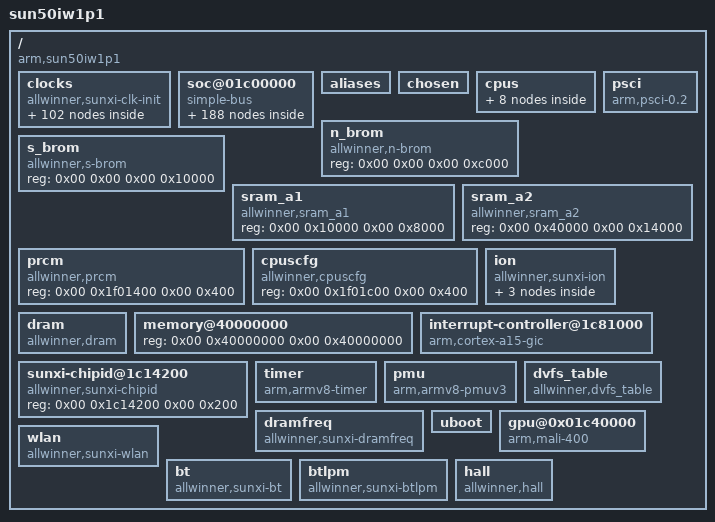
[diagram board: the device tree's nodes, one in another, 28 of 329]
/dts-v1/;

/memreserve/	0x0000000045000000 0x0000000000200000;
/memreserve/	0x0000000041010000 0x0000000000010000;
/memreserve/	0x0000000041020000 0x0000000000000800;
/memreserve/	0x0000000040100000 0x0000000000004000;
/memreserve/	0x0000000040104000 0x0000000000001000;
/memreserve/	0x0000000040105000 0x0000000000001000;
/ {
	model = "sun50iw1p1";
	compatible = "arm,sun50iw1p1\0arm,sun50iw1p1";
	interrupt-parent = < 0x01 >;
	#address-cells = < 0x02 >;
	#size-cells = < 0x02 >;

	clocks {
		compatible = "allwinner,sunxi-clk-init";
		device_type = "clocks";
		#address-cells = < 0x02 >;
		#size-cells = < 0x02 >;
		ranges;
		reg = < 0x00 0x1c20000 0x00 0x320 0x00 0x1f01400 0x00 0xb0 0x00 0x1f00060 0x00 0x04 >;

		losc {
			#clock-cells = < 0x00 >;
			compatible = "allwinner,fixed-clock";
			clock-frequency = < 0x8000 >;
			clock-output-names = "losc";
			linux,phandle = < 0x0c >;
			phandle = < 0x0c >;
		};

		iosc {
			#clock-cells = < 0x00 >;
			compatible = "allwinner,fixed-clock";
			clock-frequency = < 0xf42400 >;
			clock-output-names = "iosc";
			linux,phandle = < 0x0d >;
			phandle = < 0x0d >;
		};

		hosc {
			#clock-cells = < 0x00 >;
			compatible = "allwinner,fixed-clock";
			clock-frequency = < 0x16e3600 >;
			clock-output-names = "hosc";
			linux,phandle = < 0x06 >;
			phandle = < 0x06 >;
		};

		pll_cpu {
			#clock-cells = < 0x00 >;
			compatible = "allwinner,sunxi-pll-clock";
			lock-mode = "new";
			clock-output-names = "pll_cpu";
		};

		pll_audio {
			#clock-cells = < 0x00 >;
			compatible = "allwinner,sunxi-pll-clock";
			lock-mode = "new";
			assigned-clock-rates = < 0x1770000 >;
			clock-output-names = "pll_audio";
			linux,phandle = < 0x02 >;
			phandle = < 0x02 >;
		};

		pll_video0 {
			#clock-cells = < 0x00 >;
			compatible = "allwinner,sunxi-pll-clock";
			lock-mode = "new";
			assigned-clock-rates = < 0x11b3dc40 >;
			clock-output-names = "pll_video0";
			linux,phandle = < 0x03 >;
			phandle = < 0x03 >;
		};

		pll_ve {
			#clock-cells = < 0x00 >;
			compatible = "allwinner,sunxi-pll-clock";
			lock-mode = "new";
			clock-output-names = "pll_ve";
			linux,phandle = < 0x16 >;
			phandle = < 0x16 >;
		};

		pll_ddr0 {
			#clock-cells = < 0x00 >;
			compatible = "allwinner,sunxi-pll-clock";
			lock-mode = "new";
			clock-output-names = "pll_ddr0";
			linux,phandle = < 0x93 >;
			phandle = < 0x93 >;
		};

		pll_periph0 {
			#clock-cells = < 0x00 >;
			compatible = "allwinner,sunxi-pll-clock";
			lock-mode = "new";
			clock-output-names = "pll_periph0";
			linux,phandle = < 0x04 >;
			phandle = < 0x04 >;
		};

		pll_periph1 {
			#clock-cells = < 0x00 >;
			compatible = "allwinner,sunxi-pll-clock";
			lock-mode = "new";
			clock-output-names = "pll_periph1";
			linux,phandle = < 0x05 >;
			phandle = < 0x05 >;
		};

		pll_video1 {
			#clock-cells = < 0x00 >;
			compatible = "allwinner,sunxi-pll-clock";
			lock-mode = "new";
			assigned-clock-rates = < 0x11b3dc40 >;
			clock-output-names = "pll_video1";
		};

		pll_gpu {
			#clock-cells = < 0x00 >;
			compatible = "allwinner,sunxi-pll-clock";
			lock-mode = "new";
			clock-output-names = "pll_gpu";
			linux,phandle = < 0x96 >;
			phandle = < 0x96 >;
		};

		pll_mipi {
			#clock-cells = < 0x00 >;
			compatible = "allwinner,sunxi-pll-clock";
			lock-mode = "new";
			clock-output-names = "pll_mipi";
			linux,phandle = < 0x08 >;
			phandle = < 0x08 >;
		};

		pll_hsic {
			#clock-cells = < 0x00 >;
			compatible = "allwinner,sunxi-pll-clock";
			lock-mode = "new";
			clock-output-names = "pll_hsic";
			linux,phandle = < 0x3a >;
			phandle = < 0x3a >;
		};

		pll_de {
			#clock-cells = < 0x00 >;
			compatible = "allwinner,sunxi-pll-clock";
			lock-mode = "new";
			assigned-clock-rates = < 0x11b3dc40 >;
			clock-output-names = "pll_de";
			linux,phandle = < 0x07 >;
			phandle = < 0x07 >;
		};

		pll_ddr1 {
			#clock-cells = < 0x00 >;
			compatible = "allwinner,sunxi-pll-clock";
			lock-mode = "new";
			clock-output-names = "pll_ddr1";
			linux,phandle = < 0x94 >;
			phandle = < 0x94 >;
		};

		pll_audiox8 {
			#clock-cells = < 0x00 >;
			compatible = "allwinner,fixed-factor-clock";
			clocks = < 0x02 >;
			clock-mult = < 0x08 >;
			clock-div = < 0x01 >;
			clock-output-names = "pll_audiox8";
		};

		pll_audiox4 {
			#clock-cells = < 0x00 >;
			compatible = "allwinner,fixed-factor-clock";
			clocks = < 0x02 >;
			clock-mult = < 0x08 >;
			clock-div = < 0x02 >;
			clock-output-names = "pll_audiox4";
			linux,phandle = < 0x3c >;
			phandle = < 0x3c >;
		};

		pll_audiox2 {
			#clock-cells = < 0x00 >;
			compatible = "allwinner,fixed-factor-clock";
			clocks = < 0x02 >;
			clock-mult = < 0x08 >;
			clock-div = < 0x04 >;
			clock-output-names = "pll_audiox2";
		};

		pll_video0x2 {
			#clock-cells = < 0x00 >;
			compatible = "allwinner,fixed-factor-clock";
			clocks = < 0x03 >;
			clock-mult = < 0x02 >;
			clock-div = < 0x01 >;
			clock-output-names = "pll_video0x2";
		};

		pll_periph0x2 {
			#clock-cells = < 0x00 >;
			compatible = "allwinner,fixed-factor-clock";
			clocks = < 0x04 >;
			clock-mult = < 0x02 >;
			clock-div = < 0x01 >;
			clock-output-names = "pll_periph0x2";
			linux,phandle = < 0x7b >;
			phandle = < 0x7b >;
		};

		pll_periph1x2 {
			#clock-cells = < 0x00 >;
			compatible = "allwinner,fixed-factor-clock";
			clocks = < 0x05 >;
			clock-mult = < 0x02 >;
			clock-div = < 0x01 >;
			clock-output-names = "pll_periph1x2";
			linux,phandle = < 0x5a >;
			phandle = < 0x5a >;
		};

		pll_periph0d2 {
			#clock-cells = < 0x00 >;
			compatible = "allwinner,fixed-factor-clock";
			clocks = < 0x04 >;
			clock-mult = < 0x01 >;
			clock-div = < 0x02 >;
			clock-output-names = "pll_periph0d2";
		};

		hoscd2 {
			#clock-cells = < 0x00 >;
			compatible = "allwinner,fixed-factor-clock";
			clocks = < 0x06 >;
			clock-mult = < 0x01 >;
			clock-div = < 0x02 >;
			clock-output-names = "hoscd2";
		};

		cpu {
			#clock-cells = < 0x00 >;
			compatible = "allwinner,sunxi-periph-clock";
			clock-output-names = "cpu";
		};

		cpuapb {
			#clock-cells = < 0x00 >;
			compatible = "allwinner,sunxi-periph-clock";
			clock-output-names = "cpuapb";
		};

		axi {
			#clock-cells = < 0x00 >;
			compatible = "allwinner,sunxi-periph-clock";
			clock-output-names = "axi";
		};

		pll_periphahb0 {
			#clock-cells = < 0x00 >;
			compatible = "allwinner,sunxi-periph-clock";
			clock-output-names = "pll_periphahb0";
		};

		ahb1 {
			#clock-cells = < 0x00 >;
			compatible = "allwinner,sunxi-periph-clock";
			clock-output-names = "ahb1";
			linux,phandle = < 0x95 >;
			phandle = < 0x95 >;
		};

		apb1 {
			#clock-cells = < 0x00 >;
			compatible = "allwinner,sunxi-periph-clock";
			clock-output-names = "apb1";
		};

		apb2 {
			#clock-cells = < 0x00 >;
			compatible = "allwinner,sunxi-periph-clock";
			clock-output-names = "apb2";
			linux,phandle = < 0x7e >;
			phandle = < 0x7e >;
		};

		ahb2 {
			#clock-cells = < 0x00 >;
			compatible = "allwinner,sunxi-periph-clock";
			clock-output-names = "ahb2";
		};

		ths {
			#clock-cells = < 0x00 >;
			compatible = "allwinner,sunxi-periph-clock";
			clock-output-names = "ths";
			linux,phandle = < 0x84 >;
			phandle = < 0x84 >;
		};

		nand {
			#clock-cells = < 0x00 >;
			compatible = "allwinner,sunxi-periph-clock";
			clock-output-names = "nand";
			linux,phandle = < 0x80 >;
			phandle = < 0x80 >;
		};

		sdmmc0_mod {
			#clock-cells = < 0x00 >;
			compatible = "allwinner,sunxi-periph-clock";
			clock-output-names = "sdmmc0_mod";
			linux,phandle = < 0x60 >;
			phandle = < 0x60 >;
		};

		sdmmc0_bus {
			#clock-cells = < 0x00 >;
			compatible = "allwinner,sunxi-periph-clock";
			clock-output-names = "sdmmc0_bus";
			linux,phandle = < 0x61 >;
			phandle = < 0x61 >;
		};

		sdmmc0_rst {
			#clock-cells = < 0x00 >;
			compatible = "allwinner,sunxi-periph-clock";
			clock-output-names = "sdmmc0_rst";
			linux,phandle = < 0x62 >;
			phandle = < 0x62 >;
		};

		sdmmc1_mod {
			#clock-cells = < 0x00 >;
			compatible = "allwinner,sunxi-periph-clock";
			clock-output-names = "sdmmc1_mod";
			linux,phandle = < 0x65 >;
			phandle = < 0x65 >;
		};

		sdmmc1_bus {
			#clock-cells = < 0x00 >;
			compatible = "allwinner,sunxi-periph-clock";
			clock-output-names = "sdmmc1_bus";
			linux,phandle = < 0x66 >;
			phandle = < 0x66 >;
		};

		sdmmc1_rst {
			#clock-cells = < 0x00 >;
			compatible = "allwinner,sunxi-periph-clock";
			clock-output-names = "sdmmc1_rst";
			linux,phandle = < 0x67 >;
			phandle = < 0x67 >;
		};

		sdmmc2_mod {
			#clock-cells = < 0x00 >;
			compatible = "allwinner,sunxi-periph-clock";
			clock-output-names = "sdmmc2_mod";
			linux,phandle = < 0x5b >;
			phandle = < 0x5b >;
		};

		sdmmc2_bus {
			#clock-cells = < 0x00 >;
			compatible = "allwinner,sunxi-periph-clock";
			clock-output-names = "sdmmc2_bus";
			linux,phandle = < 0x5c >;
			phandle = < 0x5c >;
		};

		sdmmc2_rst {
			#clock-cells = < 0x00 >;
			compatible = "allwinner,sunxi-periph-clock";
			clock-output-names = "sdmmc2_rst";
			linux,phandle = < 0x5d >;
			phandle = < 0x5d >;
		};

		ts {
			#clock-cells = < 0x00 >;
			compatible = "allwinner,sunxi-periph-clock";
			clock-output-names = "ts";
		};

		ce {
			#clock-cells = < 0x00 >;
			compatible = "allwinner,sunxi-periph-clock";
			clock-output-names = "ce";
			linux,phandle = < 0x7a >;
			phandle = < 0x7a >;
		};

		spi0 {
			#clock-cells = < 0x00 >;
			compatible = "allwinner,sunxi-periph-clock";
			clock-output-names = "spi0";
			linux,phandle = < 0x52 >;
			phandle = < 0x52 >;
		};

		spi1 {
			#clock-cells = < 0x00 >;
			compatible = "allwinner,sunxi-periph-clock";
			clock-output-names = "spi1";
			linux,phandle = < 0x56 >;
			phandle = < 0x56 >;
		};

		i2s0 {
			#clock-cells = < 0x00 >;
			compatible = "allwinner,sunxi-periph-clock";
			clock-output-names = "i2s0";
			linux,phandle = < 0x42 >;
			phandle = < 0x42 >;
		};

		i2s1 {
			#clock-cells = < 0x00 >;
			compatible = "allwinner,sunxi-periph-clock";
			clock-output-names = "i2s1";
			linux,phandle = < 0x47 >;
			phandle = < 0x47 >;
		};

		i2s2 {
			#clock-cells = < 0x00 >;
			compatible = "allwinner,sunxi-periph-clock";
			clock-output-names = "i2s2";
			linux,phandle = < 0x48 >;
			phandle = < 0x48 >;
		};

		spdif {
			#clock-cells = < 0x00 >;
			compatible = "allwinner,sunxi-periph-clock";
			clock-output-names = "spdif";
			linux,phandle = < 0x49 >;
			phandle = < 0x49 >;
		};

		usbphy0 {
			#clock-cells = < 0x00 >;
			compatible = "allwinner,sunxi-periph-clock";
			clock-output-names = "usbphy0";
			linux,phandle = < 0x32 >;
			phandle = < 0x32 >;
		};

		usbphy1 {
			#clock-cells = < 0x00 >;
			compatible = "allwinner,sunxi-periph-clock";
			clock-output-names = "usbphy1";
			linux,phandle = < 0x36 >;
			phandle = < 0x36 >;
		};

		usbhsic {
			#clock-cells = < 0x00 >;
			compatible = "allwinner,sunxi-periph-clock";
			clock-output-names = "usbhsic";
			linux,phandle = < 0x38 >;
			phandle = < 0x38 >;
		};

		usbhsic12m {
			#clock-cells = < 0x00 >;
			compatible = "allwinner,sunxi-periph-clock";
			clock-output-names = "usbhsic12m";
			linux,phandle = < 0x39 >;
			phandle = < 0x39 >;
		};

		usbohci1 {
			#clock-cells = < 0x00 >;
			compatible = "allwinner,sunxi-periph-clock";
			clock-output-names = "usbohci1";
			linux,phandle = < 0x3b >;
			phandle = < 0x3b >;
		};

		usbohci0 {
			#clock-cells = < 0x00 >;
			compatible = "allwinner,sunxi-periph-clock";
			clock-output-names = "usbohci0";
			linux,phandle = < 0x35 >;
			phandle = < 0x35 >;
		};

		de {
			#clock-cells = < 0x00 >;
			compatible = "allwinner,sunxi-periph-clock";
			assigned-clock-parents = < 0x07 >;
			assigned-clock-rates = < 0x11b3dc40 >;
			clock-output-names = "de";
			linux,phandle = < 0x6a >;
			phandle = < 0x6a >;
		};

		tcon0 {
			#clock-cells = < 0x00 >;
			compatible = "allwinner,sunxi-periph-clock";
			assigned-clock-parents = < 0x08 >;
			clock-output-names = "tcon0";
			linux,phandle = < 0x6b >;
			phandle = < 0x6b >;
		};

		tcon1 {
			#clock-cells = < 0x00 >;
			compatible = "allwinner,sunxi-periph-clock";
			assigned-clock-parents = < 0x03 >;
			clock-output-names = "tcon1";
			linux,phandle = < 0x6c >;
			phandle = < 0x6c >;
		};

		deinterlace {
			#clock-cells = < 0x00 >;
			compatible = "allwinner,sunxi-periph-clock";
			clock-output-names = "deinterlace";
			linux,phandle = < 0x7c >;
			phandle = < 0x7c >;
		};

		csi_s {
			#clock-cells = < 0x00 >;
			compatible = "allwinner,sunxi-periph-clock";
			clock-output-names = "csi_s";
			linux,phandle = < 0x73 >;
			phandle = < 0x73 >;
		};

		csi_m {
			#clock-cells = < 0x00 >;
			compatible = "allwinner,sunxi-periph-clock";
			clock-output-names = "csi_m";
			linux,phandle = < 0x74 >;
			phandle = < 0x74 >;
		};

		csi_misc {
			#clock-cells = < 0x00 >;
			compatible = "allwinner,sunxi-periph-clock";
			clock-output-names = "csi_misc";
			linux,phandle = < 0x75 >;
			phandle = < 0x75 >;
		};

		ve {
			#clock-cells = < 0x00 >;
			compatible = "allwinner,sunxi-periph-clock";
			clock-output-names = "ve";
			linux,phandle = < 0x17 >;
			phandle = < 0x17 >;
		};

		adda {
			#clock-cells = < 0x00 >;
			compatible = "allwinner,sunxi-periph-clock";
			clock-output-names = "adda";
			linux,phandle = < 0x41 >;
			phandle = < 0x41 >;
		};

		addax4 {
			#clock-cells = < 0x00 >;
			compatible = "allwinner,sunxi-periph-clock";
			clock-output-names = "addax4";
		};

		avs {
			#clock-cells = < 0x00 >;
			compatible = "allwinner,sunxi-periph-clock";
			clock-output-names = "avs";
		};

		hdmi {
			#clock-cells = < 0x00 >;
			compatible = "allwinner,sunxi-periph-clock";
			assigned-clock-parents = < 0x03 >;
			clock-output-names = "hdmi";
			linux,phandle = < 0x6f >;
			phandle = < 0x6f >;
		};

		hdmi_slow {
			#clock-cells = < 0x00 >;
			compatible = "allwinner,sunxi-periph-clock";
			clock-output-names = "hdmi_slow";
			linux,phandle = < 0x70 >;
			phandle = < 0x70 >;
		};

		mbus {
			#clock-cells = < 0x00 >;
			compatible = "allwinner,sunxi-periph-clock";
			clock-output-names = "mbus";
		};

		mipidsi {
			#clock-cells = < 0x00 >;
			compatible = "allwinner,sunxi-periph-clock";
			clock-output-names = "mipidsi";
			linux,phandle = < 0x6e >;
			phandle = < 0x6e >;
		};

		gpu {
			#clock-cells = < 0x00 >;
			compatible = "allwinner,sunxi-periph-clock";
			clock-output-names = "gpu";
			linux,phandle = < 0x97 >;
			phandle = < 0x97 >;
		};

		usbehci_16 {
			#clock-cells = < 0x00 >;
			compatible = "allwinner,sunxi-periph-clock";
			clock-output-names = "usbohci_16";
		};

		usbehci1 {
			#clock-cells = < 0x00 >;
			compatible = "allwinner,sunxi-periph-clock";
			clock-output-names = "usbehci1";
			linux,phandle = < 0x37 >;
			phandle = < 0x37 >;
		};

		usbehci0 {
			#clock-cells = < 0x00 >;
			compatible = "allwinner,sunxi-periph-clock";
			clock-output-names = "usbehci0";
			linux,phandle = < 0x34 >;
			phandle = < 0x34 >;
		};

		usbotg {
			#clock-cells = < 0x00 >;
			compatible = "allwinner,sunxi-periph-clock";
			clock-output-names = "usbotg";
			linux,phandle = < 0x33 >;
			phandle = < 0x33 >;
		};

		gmac {
			#clock-cells = < 0x00 >;
			compatible = "allwinner,sunxi-periph-clock";
			clock-output-names = "gmac";
			linux,phandle = < 0x8f >;
			phandle = < 0x8f >;
		};

		sdram {
			#clock-cells = < 0x00 >;
			compatible = "allwinner,sunxi-periph-clock";
			clock-output-names = "sdram";
		};

		dma {
			#clock-cells = < 0x00 >;
			compatible = "allwinner,sunxi-periph-clock";
			clock-output-names = "dma";
			linux,phandle = < 0x0b >;
			phandle = < 0x0b >;
		};

		hwspinlock_rst {
			#clock-cells = < 0x00 >;
			compatible = "allwinner,sunxi-periph-clock";
			clock-output-names = "hwspinlock_rst";
			linux,phandle = < 0x0f >;
			phandle = < 0x0f >;
		};

		hwspinlock_bus {
			#clock-cells = < 0x00 >;
			compatible = "allwinner,sunxi-periph-clock";
			clock-output-names = "hwspinlock_bus";
			linux,phandle = < 0x10 >;
			phandle = < 0x10 >;
		};

		msgbox {
			#clock-cells = < 0x00 >;
			compatible = "allwinner,sunxi-periph-clock";
			clock-output-names = "msgbox";
			linux,phandle = < 0x0e >;
			phandle = < 0x0e >;
		};

		lvds {
			#clock-cells = < 0x00 >;
			compatible = "allwinner,sunxi-periph-clock";
			clock-output-names = "lvds";
			linux,phandle = < 0x6d >;
			phandle = < 0x6d >;
		};

		uart0 {
			#clock-cells = < 0x00 >;
			compatible = "allwinner,sunxi-periph-clock";
			clock-output-names = "uart0";
			linux,phandle = < 0x18 >;
			phandle = < 0x18 >;
		};

		uart1 {
			#clock-cells = < 0x00 >;
			compatible = "allwinner,sunxi-periph-clock";
			clock-output-names = "uart1";
			linux,phandle = < 0x1b >;
			phandle = < 0x1b >;
		};

		uart2 {
			#clock-cells = < 0x00 >;
			compatible = "allwinner,sunxi-periph-clock";
			clock-output-names = "uart2";
			linux,phandle = < 0x1e >;
			phandle = < 0x1e >;
		};

		uart3 {
			#clock-cells = < 0x00 >;
			compatible = "allwinner,sunxi-periph-clock";
			clock-output-names = "uart3";
			linux,phandle = < 0x21 >;
			phandle = < 0x21 >;
		};

		uart4 {
			#clock-cells = < 0x00 >;
			compatible = "allwinner,sunxi-periph-clock";
			clock-output-names = "uart4";
			linux,phandle = < 0x24 >;
			phandle = < 0x24 >;
		};

		scr {
			#clock-cells = < 0x00 >;
			compatible = "allwinner,sunxi-periph-clock";
			clock-output-names = "scr";
			linux,phandle = < 0x7d >;
			phandle = < 0x7d >;
		};

		twi0 {
			#clock-cells = < 0x00 >;
			compatible = "allwinner,sunxi-periph-clock";
			clock-output-names = "twi0";
			linux,phandle = < 0x27 >;
			phandle = < 0x27 >;
		};

		twi1 {
			#clock-cells = < 0x00 >;
			compatible = "allwinner,sunxi-periph-clock";
			clock-output-names = "twi1";
			linux,phandle = < 0x2a >;
			phandle = < 0x2a >;
		};

		twi2 {
			#clock-cells = < 0x00 >;
			compatible = "allwinner,sunxi-periph-clock";
			clock-output-names = "twi2";
			linux,phandle = < 0x2d >;
			phandle = < 0x2d >;
		};

		twi3 {
			#clock-cells = < 0x00 >;
			compatible = "allwinner,sunxi-periph-clock";
			clock-output-names = "twi3";
		};

		pio {
			#clock-cells = < 0x00 >;
			compatible = "allwinner,sunxi-periph-clock";
			clock-output-names = "pio";
			linux,phandle = < 0x0a >;
			phandle = < 0x0a >;
		};

		cpurcir {
			#clock-cells = < 0x00 >;
			compatible = "allwinner,sunxi-periph-cpus-clock";
			clock-output-names = "cpurcir";
			linux,phandle = < 0x12 >;
			phandle = < 0x12 >;
		};

		cpurpio {
			#clock-cells = < 0x00 >;
			compatible = "allwinner,sunxi-periph-cpus-clock";
			clock-output-names = "cpurpio";
			linux,phandle = < 0x09 >;
			phandle = < 0x09 >;
		};

		cpurpll_peri0 {
			#clock-cells = < 0x00 >;
			compatible = "allwinner,sunxi-periph-cpus-clock";
			clock-output-names = "cpurpll_peri0";
		};

		cpurcpus {
			#clock-cells = < 0x00 >;
			compatible = "allwinner,sunxi-periph-cpus-clock";
			clock-output-names = "cpurcpus";
		};

		cpurahbs {
			#clock-cells = < 0x00 >;
			compatible = "allwinner,sunxi-periph-cpus-clock";
			clock-output-names = "cpurahbs";
		};

		cpurapbs {
			#clock-cells = < 0x00 >;
			compatible = "allwinner,sunxi-periph-cpus-clock";
			clock-output-names = "cpurapbs";
		};

		losc_out {
			#clock-cells = < 0x00 >;
			compatible = "allwinner,sunxi-periph-cpus-clock";
			clock-output-names = "losc_out";
			linux,phandle = < 0x98 >;
			phandle = < 0x98 >;
		};
	};

	soc@01c00000 {
		compatible = "simple-bus";
		#address-cells = < 0x02 >;
		#size-cells = < 0x02 >;
		ranges;
		device_type = "soc";

		pinctrl@01f02c00 {
			compatible = "allwinner,sun50i-r-pinctrl";
			reg = < 0x00 0x1f02c00 0x00 0x400 >;
			interrupts = < 0x00 0x2d 0x04 >;
			clocks = < 0x09 >;
			device_type = "r_pio";
			gpio-controller;
			interrupt-controller;
			#interrupt-cells = < 0x02 >;
			#size-cells = < 0x00 >;
			#gpio-cells = < 0x06 >;
			linux,phandle = < 0x79 >;
			phandle = < 0x79 >;

			s_cir0@0 {
				allwinner,pins = "PL11";
				allwinner,function = "s_cir0";
				allwinner,muxsel = < 0x02 >;
				allwinner,drive = < 0x02 >;
				allwinner,pull = < 0x01 >;
				linux,phandle = < 0x11 >;
				phandle = < 0x11 >;
			};

			pwm16@0 {
				linux,phandle = < 0xbd >;
				phandle = < 0xbd >;
				allwinner,pins = "PL10";
				allwinner,function = "pwm16";
				allwinner,pname = "pwm_positive";
				allwinner,muxsel = < 0x02 >;
				allwinner,pull = < 0x00 >;
				allwinner,drive = < 0xffffffff >;
				allwinner,data = < 0xffffffff >;
			};

			pwm16@1 {
				linux,phandle = < 0xbe >;
				phandle = < 0xbe >;
				allwinner,pins = "PL10";
				allwinner,function = "pwm16";
				allwinner,pname = "pwm_positive";
				allwinner,muxsel = < 0x07 >;
				allwinner,pull = < 0x00 >;
				allwinner,drive = < 0xffffffff >;
				allwinner,data = < 0xffffffff >;
			};

			s_uart0@0 {
				linux,phandle = < 0xc4 >;
				phandle = < 0xc4 >;
				allwinner,pins = "PL2\0PL3";
				allwinner,function = "s_uart0";
				allwinner,pname = "s_uart0_tx\0s_uart0_rx";
				allwinner,muxsel = < 0x02 >;
				allwinner,pull = < 0xffffffff >;
				allwinner,drive = < 0xffffffff >;
				allwinner,data = < 0xffffffff >;
			};

			s_rsb0@0 {
				linux,phandle = < 0xc5 >;
				phandle = < 0xc5 >;
				allwinner,pins = "PL0\0PL1";
				allwinner,function = "s_rsb0";
				allwinner,pname = "s_rsb0_sck\0s_rsb0_sda";
				allwinner,muxsel = < 0x02 >;
				allwinner,pull = < 0x01 >;
				allwinner,drive = < 0x02 >;
				allwinner,data = < 0xffffffff >;
			};

			s_jtag0@0 {
				linux,phandle = < 0xc6 >;
				phandle = < 0xc6 >;
				allwinner,pins = "PL4\0PL5\0PL6\0PL7";
				allwinner,function = "s_jtag0";
				allwinner,pname = "s_jtag0_tms\0s_jtag0_tck\0s_jtag0_tdo\0s_jtag0_tdi";
				allwinner,muxsel = < 0x02 >;
				allwinner,pull = < 0x01 >;
				allwinner,drive = < 0x02 >;
				allwinner,data = < 0xffffffff >;
			};
		};

		pinctrl@01c20800 {
			compatible = "allwinner,sun50i-pinctrl";
			reg = < 0x00 0x1c20800 0x00 0x400 >;
			interrupts = < 0x00 0x0b 0x04 0x00 0x11 0x04 0x00 0x15 0x04 >;
			device_type = "pio";
			clocks = < 0x0a >;
			gpio-controller;
			interrupt-controller;
			#interrupt-cells = < 0x02 >;
			#size-cells = < 0x00 >;
			#gpio-cells = < 0x06 >;
			linux,phandle = < 0x30 >;
			phandle = < 0x30 >;

			sdc0@1 {
				allwinner,pins = "PF0\0PF1\0PF2\0PF3\0PF4\0PF5";
				allwinner,function = "io_disabled";
				allwinner,muxsel = < 0x07 >;
				allwinner,drive = < 0x01 >;
				allwinner,pull = < 0x01 >;
				linux,phandle = < 0x64 >;
				phandle = < 0x64 >;
			};

			sdc1@1 {
				allwinner,pins = "PG0\0PG1\0PG2\0PG3\0PG4\0PG5";
				allwinner,function = "io_disabled";
				allwinner,muxsel = < 0x07 >;
				allwinner,drive = < 0x01 >;
				allwinner,pull = < 0x01 >;
				linux,phandle = < 0x69 >;
				phandle = < 0x69 >;
			};

			sdc2@1 {
				allwinner,pins = "PC1\0PC5\0PC6\0PC8\0PC9\0PC10\0PC11\0PC12\0PC13\0PC14\0PC15\0PC16";
				allwinner,function = "io_disabled";
				allwinner,muxsel = < 0x07 >;
				allwinner,drive = < 0x01 >;
				allwinner,pull = < 0x01 >;
				linux,phandle = < 0x5f >;
				phandle = < 0x5f >;
			};

			daudio0@0 {
				allwinner,pins = "PB6\0PB3\0PB4\0PB5\0PB7";
				allwinner,function = "pcm0";
				allwinner,muxsel = < 0x03 >;
				allwinner,drive = < 0x01 >;
				allwinner,pull = < 0x00 >;
				linux,phandle = < 0x43 >;
				phandle = < 0x43 >;
			};

			daudio0_sleep@0 {
				allwinner,pins = "PB6\0PB3\0PB4\0PB5\0PB7";
				allwinner,function = "io_disabled";
				allwinner,muxsel = < 0x07 >;
				allwinner,drive = < 0x01 >;
				allwinner,pull = < 0x00 >;
				linux,phandle = < 0x44 >;
				phandle = < 0x44 >;
			};

			daudio1@0 {
				allwinner,pins = "PG10\0PG11\0PG12\0PG13";
				allwinner,function = "pcm1";
				allwinner,muxsel = < 0x03 >;
				allwinner,drive = < 0x01 >;
				allwinner,pull = < 0x00 >;
				linux,phandle = < 0x45 >;
				phandle = < 0x45 >;
			};

			daudio1_sleep@0 {
				allwinner,pins = "PG10\0PG11\0PG12\0PG13";
				allwinner,function = "io_disabled";
				allwinner,muxsel = < 0x07 >;
				allwinner,drive = < 0x01 >;
				allwinner,pull = < 0x00 >;
				linux,phandle = < 0x46 >;
				phandle = < 0x46 >;
			};

			aif3@0 {
				allwinner,pins = "PG10\0PG11\0PG12\0PG13";
				allwinner,function = "aif3";
				allwinner,muxsel = < 0x02 >;
				allwinner,drive = < 0x01 >;
				allwinner,pull = < 0x00 >;
				linux,phandle = < 0x3e >;
				phandle = < 0x3e >;
			};

			aif2_sleep@0 {
				allwinner,pins = "PB6\0PB4\0PB5\0PB7";
				allwinner,function = "io_disabled";
				allwinner,muxsel = < 0x07 >;
				allwinner,drive = < 0x01 >;
				allwinner,pull = < 0x00 >;
				linux,phandle = < 0x3f >;
				phandle = < 0x3f >;
			};

			aif3_sleep@0 {
				allwinner,pins = "PG10\0PG11\0PG12\0PG13";
				allwinner,function = "io_disabled";
				allwinner,muxsel = < 0x07 >;
				allwinner,drive = < 0x01 >;
				allwinner,pull = < 0x00 >;
				linux,phandle = < 0x40 >;
				phandle = < 0x40 >;
			};

			spdif@0 {
				allwinner,pins = "PH8";
				allwinner,function = "spdif0";
				allwinner,muxsel = < 0x02 >;
				allwinner,drive = < 0x01 >;
				allwinner,pull = < 0x00 >;
				linux,phandle = < 0x4a >;
				phandle = < 0x4a >;
			};

			spdif_sleep@0 {
				allwinner,pins = "PH8";
				allwinner,function = "io_disabled";
				allwinner,muxsel = < 0x07 >;
				allwinner,drive = < 0x01 >;
				allwinner,pull = < 0x00 >;
				linux,phandle = < 0x4b >;
				phandle = < 0x4b >;
			};

			csi0_sleep@0 {
				allwinner,pins = "PE0\0PE2\0PE3\0PE4\0PE5\0PE6\0PE7\0PE8\0PE9\0PE10\0PE11\0PE12\0PE13";
				allwinner,pname = "csi0_pck\0csi0_hsync\0csi0_vsync\0csi0_d0\0csi0_d1\0csi0_d2\0csi0_d3\0csi0_d4\0csi0_d5\0csi0_d6\0csi0_d7\0csi0_sck\0csi0_sda";
				allwinner,function = "io_disabled";
				allwinner,muxsel = < 0x07 >;
				allwinner,drive = < 0x01 >;
				allwinner,pull = < 0x00 >;
				allwinner,data = < 0x00 >;
				linux,phandle = < 0x77 >;
				phandle = < 0x77 >;
			};

			smartcard@0 {
				allwinner,pins = "PB1\0PB4\0PB5\0PB6\0PB7";
				allwinner,function = "sim0";
				allwinner,muxsel = < 0x05 >;
				allwinner,drive = < 0x01 >;
				allwinner,pull = < 0x01 >;
				linux,phandle = < 0x7f >;
				phandle = < 0x7f >;
			};

			nand0@2 {
				allwinner,pins = "PC0\0PC1\0PC2\0PC3\0PC4\0PC5\0PC6\0PC7\0PC8\0PC9\0PC10\0PC11\0PC12\0PC13\0PC14\0PC15\0PC16\0PC17\0PC18";
				allwinner,function = "io_disabled";
				allwinner,muxsel = < 0x07 >;
				allwinner,drive = < 0x01 >;
				allwinner,pull = < 0x00 >;
				linux,phandle = < 0x83 >;
				phandle = < 0x83 >;
			};

			gmac@0 {
				allwinner,pins = "PD8\0PD9\0PD10\0PD11\0PD12\0PD13\0PD14\0PD15\0PD16\0PD17\0PD18\0PD19\0PD20\0PD21\0PD22\0PD23";
				allwinner,function = "gmac0";
				allwinner,muxsel = < 0x04 >;
				allwinner,drive = < 0x03 >;
				allwinner,pull = < 0x00 >;
				linux,phandle = < 0x8e >;
				phandle = < 0x8e >;
			};

			card0_boot_para@0 {
				linux,phandle = < 0x99 >;
				phandle = < 0x99 >;
				allwinner,pins = "PF0\0PF1\0PF2\0PF3\0PF4\0PF5";
				allwinner,function = "card0_boot_para";
				allwinner,pname = "sdc_d1\0sdc_d0\0sdc_clk\0sdc_cmd\0sdc_d3\0sdc_d2";
				allwinner,muxsel = < 0x02 >;
				allwinner,pull = < 0x01 >;
				allwinner,drive = < 0x02 >;
				allwinner,data = < 0xffffffff >;
			};

			card2_boot_para@0 {
				linux,phandle = < 0x9a >;
				phandle = < 0x9a >;
				allwinner,pins = "PC1\0PC5\0PC6\0PC8\0PC9\0PC10\0PC11\0PC12\0PC13\0PC14\0PC15\0PC16";
				allwinner,function = "card2_boot_para";
				allwinner,pname = "sdc_ds\0sdc_clk\0sdc_cmd\0sdc_d0\0sdc_d1\0sdc_d2\0sdc_d3\0sdc_d4\0sdc_d5\0sdc_d6\0sdc_d7\0sdc_emmc_rst";
				allwinner,muxsel = < 0x03 >;
				allwinner,pull = < 0x01 >;
				allwinner,drive = < 0x03 >;
				allwinner,data = < 0xffffffff >;
			};

			twi_para@0 {
				linux,phandle = < 0x9b >;
				phandle = < 0x9b >;
				allwinner,pins = "PH0\0PH1";
				allwinner,function = "twi_para";
				allwinner,pname = "twi_scl\0twi_sda";
				allwinner,muxsel = < 0x02 >;
				allwinner,pull = < 0xffffffff >;
				allwinner,drive = < 0xffffffff >;
				allwinner,data = < 0xffffffff >;
			};

			uart_para@0 {
				linux,phandle = < 0x9c >;
				phandle = < 0x9c >;
				allwinner,pins = "PB8\0PB9";
				allwinner,function = "uart_para";
				allwinner,pname = "uart_debug_tx\0uart_debug_rx";
				allwinner,muxsel = < 0x04 >;
				allwinner,pull = < 0x01 >;
				allwinner,drive = < 0xffffffff >;
				allwinner,data = < 0xffffffff >;
			};

			jtag_para@0 {
				linux,phandle = < 0x9d >;
				phandle = < 0x9d >;
				allwinner,pins = "PB0\0PB1\0PB2\0PB3";
				allwinner,function = "jtag_para";
				allwinner,pname = "jtag_ms\0jtag_ck\0jtag_do\0jtag_di";
				allwinner,muxsel = < 0x04 >;
				allwinner,pull = < 0xffffffff >;
				allwinner,drive = < 0xffffffff >;
				allwinner,data = < 0xffffffff >;
			};

			gmac_para@0 {
				linux,phandle = < 0x9e >;
				phandle = < 0x9e >;
				allwinner,pins = "PA0\0PA1\0PA2\0PA3\0PA4\0PA5\0PA6\0PA7\0PA8\0PA9\0PA10\0PA11\0PA12\0PA13\0PA14\0PA15\0PA16\0PA17\0PA18\0PA19\0PA20\0PA21\0PA22\0PA23\0PA24\0PA25\0PA26\0PA27";
				allwinner,function = "gmac_para";
				allwinner,pname = "gmac_txd0\0gmac_txd1\0gmac_txd2\0gmac_txd3\0gmac_txd4\0gmac_txd5\0gmac_txd6\0gmac_txd7\0gmac_txclk\0gmac_txen\0gmac_gtxclk\0gmac_rxd0\0gmac_rxd1\0gmac_rxd2\0gmac_rxd3\0gmac_rxd4\0gmac_rxd5\0gmac_rxd6\0gmac_rxd7\0gmac_rxdv\0gmac_rxclk\0gmac_txerr\0gmac_rxerr\0gmac_col\0gmac_crs\0gmac_clkin\0gmac_mdc\0gmac_mdio";
				allwinner,muxsel = < 0x02 >;
				allwinner,pull = < 0xffffffff >;
				allwinner,drive = < 0xffffffff >;
				allwinner,data = < 0xffffffff >;
			};

			twi0@0 {
				linux,phandle = < 0x9f >;
				phandle = < 0x9f >;
				allwinner,pins = "PH0\0PH1";
				allwinner,function = "twi0";
				allwinner,pname = "twi0_scl\0twi0_sda";
				allwinner,muxsel = < 0x02 >;
				allwinner,pull = < 0xffffffff >;
				allwinner,drive = < 0xffffffff >;
				allwinner,data = < 0xffffffff >;
			};

			twi0@1 {
				linux,phandle = < 0xa0 >;
				phandle = < 0xa0 >;
				allwinner,pins = "PH0\0PH1";
				allwinner,function = "twi0";
				allwinner,pname = "twi0_scl\0twi0_sda";
				allwinner,muxsel = < 0x07 >;
				allwinner,pull = < 0xffffffff >;
				allwinner,drive = < 0xffffffff >;
				allwinner,data = < 0xffffffff >;
			};

			twi1@0 {
				linux,phandle = < 0xa1 >;
				phandle = < 0xa1 >;
				allwinner,pins = "PH2\0PH3";
				allwinner,function = "twi1";
				allwinner,pname = "twi1_scl\0twi1_sda";
				allwinner,muxsel = < 0x02 >;
				allwinner,pull = < 0xffffffff >;
				allwinner,drive = < 0xffffffff >;
				allwinner,data = < 0xffffffff >;
			};

			twi1@1 {
				linux,phandle = < 0xa2 >;
				phandle = < 0xa2 >;
				allwinner,pins = "PH2\0PH3";
				allwinner,function = "twi1";
				allwinner,pname = "twi1_scl\0twi1_sda";
				allwinner,muxsel = < 0x07 >;
				allwinner,pull = < 0xffffffff >;
				allwinner,drive = < 0xffffffff >;
				allwinner,data = < 0xffffffff >;
			};

			twi2@0 {
				linux,phandle = < 0xa3 >;
				phandle = < 0xa3 >;
				allwinner,pins = "PE14\0PE15";
				allwinner,function = "twi2";
				allwinner,pname = "twi2_scl\0twi2_sda";
				allwinner,muxsel = < 0x03 >;
				allwinner,pull = < 0xffffffff >;
				allwinner,drive = < 0xffffffff >;
				allwinner,data = < 0xffffffff >;
			};

			twi2@1 {
				linux,phandle = < 0xa4 >;
				phandle = < 0xa4 >;
				allwinner,pins = "PE14\0PE15";
				allwinner,function = "twi2";
				allwinner,pname = "twi2_scl\0twi2_sda";
				allwinner,muxsel = < 0x07 >;
				allwinner,pull = < 0xffffffff >;
				allwinner,drive = < 0xffffffff >;
				allwinner,data = < 0xffffffff >;
			};

			uart0@0 {
				linux,phandle = < 0xa5 >;
				phandle = < 0xa5 >;
				allwinner,pins = "PB8\0PB9";
				allwinner,function = "uart0";
				allwinner,pname = "uart0_tx\0uart0_rx";
				allwinner,muxsel = < 0x04 >;
				allwinner,pull = < 0x01 >;
				allwinner,drive = < 0xffffffff >;
				allwinner,data = < 0xffffffff >;
			};

			uart0@1 {
				linux,phandle = < 0xa6 >;
				phandle = < 0xa6 >;
				allwinner,pins = "PB8\0PB9";
				allwinner,function = "uart0";
				allwinner,pname = "uart0_tx\0uart0_rx";
				allwinner,muxsel = < 0x07 >;
				allwinner,pull = < 0x01 >;
				allwinner,drive = < 0xffffffff >;
				allwinner,data = < 0xffffffff >;
			};

			uart1@0 {
				linux,phandle = < 0xa7 >;
				phandle = < 0xa7 >;
				allwinner,pins = "PG6\0PG7\0PG8\0PG9";
				allwinner,function = "uart1";
				allwinner,pname = "uart1_tx\0uart1_rx\0uart1_rts\0uart1_cts";
				allwinner,muxsel = < 0x02 >;
				allwinner,pull = < 0x01 >;
				allwinner,drive = < 0xffffffff >;
				allwinner,data = < 0xffffffff >;
			};

			uart1@1 {
				linux,phandle = < 0xa8 >;
				phandle = < 0xa8 >;
				allwinner,pins = "PG6\0PG7\0PG8\0PG9";
				allwinner,function = "uart1";
				allwinner,pname = "uart1_tx\0uart1_rx\0uart1_rts\0uart1_cts";
				allwinner,muxsel = < 0x07 >;
				allwinner,pull = < 0x01 >;
				allwinner,drive = < 0xffffffff >;
				allwinner,data = < 0xffffffff >;
			};

			uart2@0 {
				linux,phandle = < 0xa9 >;
				phandle = < 0xa9 >;
				allwinner,pins = "PB0\0PB1\0PB2\0PB3";
				allwinner,function = "uart2";
				allwinner,pname = "uart2_tx\0uart2_rx\0uart2_rts\0uart2_cts";
				allwinner,muxsel = < 0x02 >;
				allwinner,pull = < 0x01 >;
				allwinner,drive = < 0xffffffff >;
				allwinner,data = < 0xffffffff >;
			};

			uart2@1 {
				linux,phandle = < 0xaa >;
				phandle = < 0xaa >;
				allwinner,pins = "PB0\0PB1\0PB2\0PB3";
				allwinner,function = "uart2";
				allwinner,pname = "uart2_tx\0uart2_rx\0uart2_rts\0uart2_cts";
				allwinner,muxsel = < 0x07 >;
				allwinner,pull = < 0x01 >;
				allwinner,drive = < 0xffffffff >;
				allwinner,data = < 0xffffffff >;
			};

			uart3@0 {
				linux,phandle = < 0xab >;
				phandle = < 0xab >;
				allwinner,pins = "PH4\0PH5\0PH6\0PH7";
				allwinner,function = "uart3";
				allwinner,pname = "uart3_tx\0uart3_rx\0uart3_rts\0uart3_cts";
				allwinner,muxsel = < 0x02 >;
				allwinner,pull = < 0x01 >;
				allwinner,drive = < 0xffffffff >;
				allwinner,data = < 0xffffffff >;
			};

			uart3@1 {
				linux,phandle = < 0xac >;
				phandle = < 0xac >;
				allwinner,pins = "PH4\0PH5\0PH6\0PH7";
				allwinner,function = "uart3";
				allwinner,pname = "uart3_tx\0uart3_rx\0uart3_rts\0uart3_cts";
				allwinner,muxsel = < 0x07 >;
				allwinner,pull = < 0x01 >;
				allwinner,drive = < 0xffffffff >;
				allwinner,data = < 0xffffffff >;
			};

			uart4@0 {
				linux,phandle = < 0xad >;
				phandle = < 0xad >;
				allwinner,pins = "PD2\0PD3\0PD4\0PD5";
				allwinner,function = "uart4";
				allwinner,pname = "uart4_tx\0uart4_rx\0uart4_rts\0uart4_cts";
				allwinner,muxsel = < 0x03 >;
				allwinner,pull = < 0x01 >;
				allwinner,drive = < 0xffffffff >;
				allwinner,data = < 0xffffffff >;
			};

			uart4@1 {
				linux,phandle = < 0xae >;
				phandle = < 0xae >;
				allwinner,pins = "PD2\0PD3\0PD4\0PD5";
				allwinner,function = "uart4";
				allwinner,pname = "uart4_tx\0uart4_rx\0uart4_rts\0uart4_cts";
				allwinner,muxsel = < 0x07 >;
				allwinner,pull = < 0x01 >;
				allwinner,drive = < 0xffffffff >;
				allwinner,data = < 0xffffffff >;
			};

			spi0@0 {
				linux,phandle = < 0xaf >;
				phandle = < 0xaf >;
				allwinner,pins = "PC3";
				allwinner,function = "spi0";
				allwinner,pname = "spi0_cs0";
				allwinner,muxsel = < 0x04 >;
				allwinner,pull = < 0x01 >;
				allwinner,drive = < 0xffffffff >;
				allwinner,data = < 0xffffffff >;
			};

			spi0@1 {
				linux,phandle = < 0xb0 >;
				phandle = < 0xb0 >;
				allwinner,pins = "PC2\0PC0\0PC1";
				allwinner,function = "spi0";
				allwinner,pname = "spi0_sclk\0spi0_mosi\0spi0_miso";
				allwinner,muxsel = < 0x04 >;
				allwinner,pull = < 0xffffffff >;
				allwinner,drive = < 0xffffffff >;
				allwinner,data = < 0xffffffff >;
			};

			spi0@2 {
				linux,phandle = < 0xb1 >;
				phandle = < 0xb1 >;
				allwinner,pins = "PC3";
				allwinner,function = "spi0";
				allwinner,pname = "spi0_cs0";
				allwinner,muxsel = < 0x07 >;
				allwinner,pull = < 0x01 >;
				allwinner,drive = < 0xffffffff >;
				allwinner,data = < 0xffffffff >;
			};

			spi0@3 {
				linux,phandle = < 0xb2 >;
				phandle = < 0xb2 >;
				allwinner,pins = "PC2\0PC0\0PC1";
				allwinner,function = "spi0";
				allwinner,pname = "spi0_sclk\0spi0_mosi\0spi0_miso";
				allwinner,muxsel = < 0x07 >;
				allwinner,pull = < 0xffffffff >;
				allwinner,drive = < 0xffffffff >;
				allwinner,data = < 0xffffffff >;
			};

			spi1@0 {
				linux,phandle = < 0xb3 >;
				phandle = < 0xb3 >;
				allwinner,pins = "PD0";
				allwinner,function = "spi1";
				allwinner,pname = "spi1_cs0";
				allwinner,muxsel = < 0x04 >;
				allwinner,pull = < 0x01 >;
				allwinner,drive = < 0xffffffff >;
				allwinner,data = < 0xffffffff >;
			};

			spi1@1 {
				linux,phandle = < 0xb4 >;
				phandle = < 0xb4 >;
				allwinner,pins = "PD1\0PD2\0PD3";
				allwinner,function = "spi1";
				allwinner,pname = "spi1_sclk\0spi1_mosi\0spi1_miso";
				allwinner,muxsel = < 0x04 >;
				allwinner,pull = < 0xffffffff >;
				allwinner,drive = < 0xffffffff >;
				allwinner,data = < 0xffffffff >;
			};

			spi1@2 {
				linux,phandle = < 0xb5 >;
				phandle = < 0xb5 >;
				allwinner,pins = "PD0";
				allwinner,function = "spi1";
				allwinner,pname = "spi1_cs0";
				allwinner,muxsel = < 0x07 >;
				allwinner,pull = < 0x01 >;
				allwinner,drive = < 0xffffffff >;
				allwinner,data = < 0xffffffff >;
			};

			spi1@3 {
				linux,phandle = < 0xb6 >;
				phandle = < 0xb6 >;
				allwinner,pins = "PD1\0PD2\0PD3";
				allwinner,function = "spi1";
				allwinner,pname = "spi1_sclk\0spi1_mosi\0spi1_miso";
				allwinner,muxsel = < 0x07 >;
				allwinner,pull = < 0xffffffff >;
				allwinner,drive = < 0xffffffff >;
				allwinner,data = < 0xffffffff >;
			};

			nand0@0 {
				linux,phandle = < 0xb7 >;
				phandle = < 0xb7 >;
				allwinner,pins = "PC0\0PC1\0PC2\0PC5\0PC8\0PC9\0PC10\0PC11\0PC12\0PC13\0PC14\0PC15\0PC16";
				allwinner,function = "nand0";
				allwinner,pname = "nand0_we\0nand0_ale\0nand0_cle\0nand0_nre\0nand0_d0\0nand0_d1\0nand0_d2\0nand0_d3\0nand0_d4\0nand0_d5\0nand0_d6\0nand0_d7\0nand0_ndqs";
				allwinner,muxsel = < 0x02 >;
				allwinner,pull = < 0x00 >;
				allwinner,drive = < 0x01 >;
				allwinner,data = < 0xffffffff >;
			};

			nand0@1 {
				linux,phandle = < 0xb8 >;
				phandle = < 0xb8 >;
				allwinner,pins = "PC3\0PC4\0PC6\0PC7\0PC17\0PC18";
				allwinner,function = "nand0";
				allwinner,pname = "nand0_ce1\0nand0_ce0\0nand0_rb0\0nand0_rb1\0nand0_ce2\0nand0_ce3";
				allwinner,muxsel = < 0x02 >;
				allwinner,pull = < 0x01 >;
				allwinner,drive = < 0x01 >;
				allwinner,data = < 0xffffffff >;
			};

			lcd0@0 {
				linux,phandle = < 0xb9 >;
				phandle = < 0xb9 >;
				allwinner,pins = "PD0\0PD1\0PD2\0PD3\0PD4\0PD5\0PD6\0PD7\0PD8\0PD9\0PD10\0PD11\0PD12\0PD13\0PD14\0PD15\0PD16\0PD17\0PD18\0PD19\0PD20\0PD21";
				allwinner,function = "lcd0";
				allwinner,pname = "lcdd2\0lcdd3\0lcdd4\0lcdd5\0lcdd6\0lcdd7\0lcdd10\0lcdd11\0lcdd12\0lcdd13\0lcdd14\0lcdd15\0lcdd18\0lcdd19\0lcdd20\0lcdd21\0lcdd22\0lcdd23\0lcdclk\0lcdde\0lcdhsync\0lcdvsync";
				allwinner,muxsel = < 0x02 >;
				allwinner,pull = < 0x00 >;
				allwinner,drive = < 0x03 >;
				allwinner,data = < 0xffffffff >;
			};

			lcd0@1 {
				linux,phandle = < 0xba >;
				phandle = < 0xba >;
				allwinner,pins = "PD12\0PD13\0PD14\0PD15\0PD16\0PD17\0PD18\0PD19\0PD20\0PD21";
				allwinner,function = "lcd0";
				allwinner,pname = "lcdd0\0lcdd1\0lcdd2\0lcdd3\0lcdd4\0lcdd5\0lcdd6\0lcdd7\0lcdd8\0lcdd9";
				allwinner,muxsel = < 0x07 >;
				allwinner,pull = < 0x00 >;
				allwinner,drive = < 0xffffffff >;
				allwinner,data = < 0xffffffff >;
			};

			pwm0@0 {
				linux,phandle = < 0xbb >;
				phandle = < 0xbb >;
				allwinner,pins = "PD22";
				allwinner,function = "pwm0";
				allwinner,pname = "pwm_positive";
				allwinner,muxsel = < 0x02 >;
				allwinner,pull = < 0x00 >;
				allwinner,drive = < 0xffffffff >;
				allwinner,data = < 0xffffffff >;
			};

			pwm0@1 {
				linux,phandle = < 0xbc >;
				phandle = < 0xbc >;
				allwinner,pins = "PD22";
				allwinner,function = "pwm0";
				allwinner,pname = "pwm_positive";
				allwinner,muxsel = < 0x07 >;
				allwinner,pull = < 0x00 >;
				allwinner,drive = < 0xffffffff >;
				allwinner,data = < 0xffffffff >;
			};

			csi0@0 {
				linux,phandle = < 0xbf >;
				phandle = < 0xbf >;
				allwinner,pins = "PE0\0PE2\0PE3\0PE4\0PE5\0PE6\0PE7\0PE8\0PE9\0PE10\0PE11\0PE12\0PE13";
				allwinner,function = "csi0";
				allwinner,pname = "csi0_pck\0csi0_hsync\0csi0_vsync\0csi0_d0\0csi0_d1\0csi0_d2\0csi0_d3\0csi0_d4\0csi0_d5\0csi0_d6\0csi0_d7\0csi0_sck\0csi0_sda";
				allwinner,muxsel = < 0x02 >;
				allwinner,pull = < 0xffffffff >;
				allwinner,drive = < 0xffffffff >;
				allwinner,data = < 0xffffffff >;
			};

			sdc0@0 {
				linux,phandle = < 0xc0 >;
				phandle = < 0xc0 >;
				allwinner,pins = "PF0\0PF1\0PF2\0PF3\0PF4\0PF5";
				allwinner,function = "sdc0";
				allwinner,pname = "sdc0_d1\0sdc0_d0\0sdc0_clk\0sdc0_cmd\0sdc0_d3\0sdc0_d2";
				allwinner,muxsel = < 0x02 >;
				allwinner,pull = < 0x01 >;
				allwinner,drive = < 0x02 >;
				allwinner,data = < 0xffffffff >;
			};

			sdc1@0 {
				linux,phandle = < 0xc1 >;
				phandle = < 0xc1 >;
				allwinner,pins = "PG0\0PG1\0PG2\0PG3\0PG4\0PG5";
				allwinner,function = "sdc1";
				allwinner,pname = "sdc1_clk\0sdc1_cmd\0sdc1_d0\0sdc1_d1\0sdc1_d2\0sdc1_d3";
				allwinner,muxsel = < 0x02 >;
				allwinner,pull = < 0x01 >;
				allwinner,drive = < 0x03 >;
				allwinner,data = < 0xffffffff >;
			};

			sdc2@0 {
				linux,phandle = < 0xc2 >;
				phandle = < 0xc2 >;
				allwinner,pins = "PC1\0PC5\0PC6\0PC8\0PC9\0PC10\0PC11\0PC12\0PC13\0PC14\0PC15\0PC16";
				allwinner,function = "sdc2";
				allwinner,pname = "sdc2_ds\0sdc2_clk\0sdc2_cmd\0sdc2_d0\0sdc2_d1\0sdc2_d2\0sdc2_d3\0sdc2_d4\0sdc2_d5\0sdc2_d6\0sdc2_d7\0sdc2_emmc_rst";
				allwinner,muxsel = < 0x03 >;
				allwinner,pull = < 0x01 >;
				allwinner,drive = < 0x03 >;
				allwinner,data = < 0xffffffff >;
			};

			codec@0 {
				linux,phandle = < 0xc3 >;
				phandle = < 0xc3 >;
				allwinner,pins = "PH7\0PL11\0PL10";
				allwinner,function = "codec";
				allwinner,pname = "gpio-spk\0gpio-mid\0gpio-uart";
				allwinner,muxsel = < 0x02 >;
				allwinner,pull = < 0x01 >;
				allwinner,drive = < 0xffffffff >;
				allwinner,data = < 0xffffffff >;
			};

			Vdevice@0 {
				linux,phandle = < 0xc7 >;
				phandle = < 0xc7 >;
				allwinner,pins = "PB1\0PB2";
				allwinner,function = "Vdevice";
				allwinner,pname = "Vdevice_0\0Vdevice_1";
				allwinner,muxsel = < 0x04 >;
				allwinner,pull = < 0x01 >;
				allwinner,drive = < 0x02 >;
				allwinner,data = < 0xffffffff >;
			};
		};

		pinctrl@0 {
			compatible = "allwinner,axp-pinctrl";
			gpio-controller;
			#size-cells = < 0x00 >;
			#gpio-cells = < 0x06 >;
			device_type = "axp_pio";
			linux,phandle = < 0x31 >;
			phandle = < 0x31 >;
		};

		dma-controller@01c02000 {
			compatible = "allwinner,sun50i-dma";
			reg = < 0x00 0x1c02000 0x00 0x1000 >;
			interrupts = < 0x00 0x32 0x04 >;
			clocks = < 0x0b >;
			#dma-cells = < 0x01 >;
		};

		mbus-controller@01c62000 {
			compatible = "allwinner,sun50i-mbus";
			reg = < 0x00 0x1c62000 0x00 0x110 >;
			#mbus-cells = < 0x01 >;
		};

		arisc {
			compatible = "allwinner,sunxi-arisc";
			#address-cells = < 0x02 >;
			#size-cells = < 0x02 >;
			clocks = < 0x0c 0x0d 0x06 0x04 >;
			clock-names = "losc\0iosc\0hosc\0pll_periph0";
			powchk_used = < 0x00 >;
			power_reg = < 0x2309621 >;
			system_power = < 0x32 >;
		};

		arisc_space {
			compatible = "allwinner,arisc_space";
			space1 = < 0x40000 0x00 0x14000 >;
			space2 = < 0x40100000 0x18000 0x4000 >;
			space3 = < 0x40104000 0x00 0x1000 >;
			space4 = < 0x40105000 0x00 0x1000 >;
		};

		standby_space {
			compatible = "allwinner,standby_space";
			space1 = < 0x41020000 0x00 0x800 >;
		};

		msgbox@1c17000 {
			compatible = "allwinner,msgbox";
			clocks = < 0x0e >;
			clock-names = "clk_msgbox";
			reg = < 0x00 0x1c17000 0x00 0x1000 >;
			interrupts = < 0x00 0x31 0x01 >;
			status = "okay";
		};

		hwspinlock@1c18000 {
			compatible = "allwinner,sunxi-hwspinlock";
			clocks = < 0x0f 0x10 >;
			clock-names = "clk_hwspinlock_rst\0clk_hwspinlock_bus";
			reg = < 0x00 0x1c18000 0x00 0x1000 >;
			status = "okay";
			num-locks = < 0x08 >;
		};

		s_cir@1f02000 {
			compatible = "allwinner,s_cir";
			reg = < 0x00 0x1f02000 0x00 0x400 >;
			interrupts = < 0x00 0x25 0x04 >;
			pinctrl-names = "default";
			pinctrl-0 = < 0x11 >;
			clocks = < 0x06 0x12 >;
			supply = "vcc-pl";
			ir_power_key_code = < 0x00 >;
			ir_addr_code = < 0x00 >;
			status = "disabled";
			device_type = "s_cir0";
		};

		s_uart@1f02800 {
			compatible = "allwinner,s_uart";
			reg = < 0x00 0x1f02800 0x00 0x400 >;
			interrupts = < 0x00 0x26 0x04 >;
			pinctrl-names = "default";
			status = "okay";
			device_type = "s_uart0";
			pinctrl-0 = < 0xc4 >;
		};

		s_rsb@1f03400 {
			compatible = "allwinner,s_rsb";
			reg = < 0x00 0x1f03400 0x00 0x400 >;
			interrupts = < 0x00 0x27 0x04 >;
			pinctrl-names = "default";
			status = "okay";
			device_type = "s_rsb0";
			pinctrl-0 = < 0xc5 >;
		};

		s_jtag0 {
			compatible = "allwinner,s_jtag";
			pinctrl-names = "default";
			status = "disabled";
			device_type = "s_jtag0";
			pinctrl-0 = < 0xc6 >;
		};

		timer@1c20c00 {
			compatible = "allwinner,sunxi-timer";
			device_type = "timer";
			reg = < 0x00 0x1c20c00 0x00 0x90 >;
			interrupts = < 0x00 0x12 0x01 >;
			clock-frequency = < 0x16e3600 >;
			timer-prescale = < 0x10 >;
		};

		rtc@01f00000 {
			compatible = "allwinner,sun50i-rtc";
			device_type = "rtc";
			reg = < 0x00 0x1f00000 0x00 0x218 >;
			interrupts = < 0x00 0x28 0x04 >;
			gpr_offset = < 0x100 >;
			gpr_len = < 0x04 >;
		};

		ve@01c0e000 {
			compatible = "allwinner,sunxi-cedar-ve";
			reg = < 0x00 0x1c0e000 0x00 0x1000 0x00 0x1c00000 0x00 0x10 0x00 0x1c20000 0x00 0x800 >;
			interrupts = < 0x00 0x3a 0x04 >;
			clocks = < 0x16 0x17 >;
		};

		uart@01c28000 {
			compatible = "allwinner,sun50i-uart";
			device_type = "uart0";
			reg = < 0x00 0x1c28000 0x00 0x400 >;
			interrupts = < 0x00 0x00 0x04 >;
			clocks = < 0x18 >;
			pinctrl-names = "default\0sleep";
			uart0_port = < 0x00 >;
			uart0_type = < 0x02 >;
			status = "okay";
			pinctrl-0 = < 0xa5 >;
			pinctrl-1 = < 0xa6 >;
		};

		uart@01c28400 {
			compatible = "allwinner,sun50i-uart";
			device_type = "uart1";
			reg = < 0x00 0x1c28400 0x00 0x400 >;
			interrupts = < 0x00 0x01 0x04 >;
			clocks = < 0x1b >;
			pinctrl-names = "default\0sleep";
			uart1_port = < 0x01 >;
			uart1_type = < 0x04 >;
			status = "okay";
			pinctrl-0 = < 0xa7 >;
			pinctrl-1 = < 0xa8 >;
		};

		uart@01c28800 {
			compatible = "allwinner,sun50i-uart";
			device_type = "uart2";
			reg = < 0x00 0x1c28800 0x00 0x400 >;
			interrupts = < 0x00 0x02 0x04 >;
			clocks = < 0x1e >;
			pinctrl-names = "default\0sleep";
			uart2_port = < 0x02 >;
			uart2_type = < 0x04 >;
			status = "disabled";
			pinctrl-0 = < 0xa9 >;
			pinctrl-1 = < 0xaa >;
		};

		uart@01c28c00 {
			compatible = "allwinner,sun50i-uart";
			device_type = "uart3";
			reg = < 0x00 0x1c28c00 0x00 0x400 >;
			interrupts = < 0x00 0x03 0x04 >;
			clocks = < 0x21 >;
			pinctrl-names = "default\0sleep";
			uart3_port = < 0x03 >;
			uart3_type = < 0x04 >;
			status = "disabled";
			pinctrl-0 = < 0xab >;
			pinctrl-1 = < 0xac >;
		};

		uart@01c29000 {
			compatible = "allwinner,sun50i-uart";
			device_type = "uart4";
			reg = < 0x00 0x1c29000 0x00 0x400 >;
			interrupts = < 0x00 0x04 0x04 >;
			clocks = < 0x24 >;
			pinctrl-names = "default\0sleep";
			uart4_port = < 0x04 >;
			uart4_type = < 0x04 >;
			status = "disabled";
			pinctrl-0 = < 0xad >;
			pinctrl-1 = < 0xae >;
		};

		twi@0x01c2ac00 {
			#address-cells = < 0x01 >;
			#size-cells = < 0x00 >;
			compatible = "allwinner,sun50i-twi";
			device_type = "twi0";
			reg = < 0x00 0x1c2ac00 0x00 0x400 >;
			interrupts = < 0x00 0x06 0x04 >;
			clocks = < 0x27 >;
			clock-frequency = < 0x61a80 >;
			pinctrl-names = "default\0sleep";
			status = "okay";
			pinctrl-0 = < 0x9f >;
			pinctrl-1 = < 0xa0 >;
		};

		twi@0x01c2b000 {
			#address-cells = < 0x01 >;
			#size-cells = < 0x00 >;
			compatible = "allwinner,sun50i-twi";
			device_type = "twi1";
			reg = < 0x00 0x1c2b000 0x00 0x400 >;
			interrupts = < 0x00 0x07 0x04 >;
			clocks = < 0x2a >;
			clock-frequency = < 0x30d40 >;
			pinctrl-names = "default\0sleep";
			status = "okay";
			pinctrl-0 = < 0xa1 >;
			pinctrl-1 = < 0xa2 >;
		};

		twi@0x01c2b400 {
			#address-cells = < 0x01 >;
			#size-cells = < 0x00 >;
			compatible = "allwinner,sun50i-twi";
			device_type = "twi2";
			reg = < 0x00 0x1c2b400 0x00 0x400 >;
			interrupts = < 0x00 0x08 0x04 >;
			clocks = < 0x2d >;
			clock-frequency = < 0x30d40 >;
			pinctrl-names = "default\0sleep";
			status = "disabled";
			pinctrl-0 = < 0xa3 >;
			pinctrl-1 = < 0xa4 >;
		};

		usbc0@0 {
			device_type = "usbc0";
			compatible = "allwinner,sunxi-otg-manager";
			usb_port_type = < 0x01 >;
			usb_detect_type = < 0x00 >;
			usb_det_vbus_gpio = "axp_ctrl";
			usb_host_init_state = < 0x00 >;
			usb_regulator_io = "nocare";
			usb_wakeup_suspend = < 0x00 >;
			usb_luns = < 0x03 >;
			usb_serial_unique = < 0x01 >;
			usb_serial_number = "20080411";
			rndis_wceis = < 0x01 >;
			status = "okay";
			usb_id_gpio;
			usb_drv_vbus_gpio = < 0x31 0xfffe 0x03 0x01 0x00 0xffffffff 0x00 >;
		};

		udc-controller@0x01c19000 {
			compatible = "allwinner,sunxi-udc";
			reg = < 0x00 0x1c19000 0x00 0x1000 0x00 0x1c00000 0x00 0x100 >;
			interrupts = < 0x00 0x47 0x04 >;
			clocks = < 0x32 0x33 >;
			status = "okay";
		};

		ehci0-controller@0x01c1a000 {
			compatible = "allwinner,sunxi-ehci0";
			reg = < 0x00 0x1c1a000 0x00 0xfff 0x00 0x1c00000 0x00 0x100 0x00 0x1c19000 0x00 0x1000 >;
			interrupts = < 0x00 0x48 0x04 >;
			clocks = < 0x32 0x34 >;
			hci_ctrl_no = < 0x00 >;
			status = "okay";
		};

		ohci0-controller@0x01c1a400 {
			compatible = "allwinner,sunxi-ohci0";
			reg = < 0x00 0x1c1a000 0x00 0xfff 0x00 0x1c00000 0x00 0x100 0x00 0x1c19000 0x00 0x1000 >;
			interrupts = < 0x00 0x49 0x04 >;
			clocks = < 0x32 0x35 >;
			hci_ctrl_no = < 0x00 >;
			status = "okay";
		};

		usbc1@0 {
			device_type = "usbc1";
			usb_host_init_state = < 0x01 >;
			usb_regulator_io = "nocare";
			usb_wakeup_suspend = < 0x00 >;
			usb_hsic_used = < 0x00 >;
			usb_hsic_regulator_io = "vcc-hsic-12";
			usb_hsic_ctrl = < 0x00 >;
			usb_hsic_usb3503_flag = < 0x00 >;
			status = "okay";
			usb_port_type = < 0x01 >;
			usb_detect_type = < 0x00 >;
			usb_drv_vbus_gpio = < 0x30 0x01 0x06 0x01 0x00 0xffffffff 0x00 >;
			usb_hsic_rdy_gpio;
			usb_hsic_hub_connect_gpio;
			usb_hsic_int_n_gpio;
			usb_hsic_reset_n_gpio;
		};

		ehci1-controller@0x01c1b000 {
			compatible = "allwinner,sunxi-ehci1";
			reg = < 0x00 0x1c1b000 0x00 0xfff 0x00 0x1c00000 0x00 0x100 0x00 0x1c19000 0x00 0x1000 >;
			interrupts = < 0x00 0x4a 0x04 >;
			clocks = < 0x36 0x37 0x38 0x39 0x3a >;
			hci_ctrl_no = < 0x01 >;
			status = "okay";
		};

		ohci1-controller@0x01c1b400 {
			compatible = "allwinner,sunxi-ohci1";
			reg = < 0x00 0x1c1b000 0x00 0xfff 0x00 0x1c00000 0x00 0x100 0x00 0x1c19000 0x00 0x1000 >;
			interrupts = < 0x00 0x4b 0x04 >;
			clocks = < 0x36 0x3b >;
			hci_ctrl_no = < 0x01 >;
			status = "okay";
		};

		codec@0x01c22c00 {
			compatible = "allwinner,sunxi-internal-codec";
			reg = < 0x00 0x1c22c00 0x00 0x478 0x00 0x1f015c0 0x00 0x00 >;
			clocks = < 0x3c >;
			pinctrl-names = "aif2-default\0aif3-default\0aif2-sleep\0aif3-sleep";
			pinctrl-1 = < 0x3e >;
			pinctrl-2 = < 0x3f >;
			pinctrl-3 = < 0x40 >;
			gpio-spk = < 0x30 0x07 0x07 0x01 0x01 0x01 0x01 >;
			headphonevol = < 0x3b >;
			spkervol = < 0x1f >;
			earpiecevol = < 0x1e >;
			maingain = < 0x04 >;
			headsetmicgain = < 0x04 >;
			adcagc_cfg = < 0x00 >;
			adcdrc_cfg = < 0x00 >;
			adchpf_cfg = < 0x01 >;
			dacdrc_cfg = < 0x00 >;
			dachpf_cfg = < 0x00 >;
			aif1_lrlk_div = < 0x40 >;
			aif2_lrlk_div = < 0x40 >;
			aif2config = < 0x00 >;
			aif3config = < 0x00 >;
			pa_sleep_time = < 0x0a >;
			dac_digital_vol = < 0x9898 >;
			status = "okay";
			linux,phandle = < 0x4d >;
			phandle = < 0x4d >;
			device_type = "codec";
			pinctrl-0 = < 0xc3 >;
		};

		i2s0-controller@0x01c22c00 {
			compatible = "allwinner,sunxi-internal-i2s";
			reg = < 0x00 0x1c22c00 0x00 0x478 >;
			clocks = < 0x02 0x41 >;
			status = "okay";
			linux,phandle = < 0x4c >;
			phandle = < 0x4c >;
			device_type = "i2s";
		};

		daudio@0x01c22000 {
			compatible = "allwinner,sunxi-daudio";
			reg = < 0x00 0x1c22000 0x00 0x58 >;
			clocks = < 0x02 0x42 >;
			pinctrl-names = "default\0sleep";
			pinctrl-0 = < 0x43 >;
			pinctrl-1 = < 0x44 >;
			pcm_lrck_period = < 0x20 >;
			pcm_lrckr_period = < 0x01 >;
			slot_width_select = < 0x20 >;
			pcm_lsb_first = < 0x00 >;
			tx_data_mode = < 0x00 >;
			rx_data_mode = < 0x00 >;
			daudio_master = < 0x04 >;
			audio_format = < 0x01 >;
			signal_inversion = < 0x01 >;
			frametype = < 0x00 >;
			tdm_config = < 0x01 >;
			tdm_num = < 0x00 >;
			status = "disabled";
			linux,phandle = < 0x4e >;
			phandle = < 0x4e >;
			device_type = "daudio0";
		};

		daudio@0x01c22400 {
			compatible = "allwinner,sunxi-daudio";
			reg = < 0x00 0x1c22400 0x00 0x58 >;
			pinctrl-names = "default\0sleep";
			pinctrl-0 = < 0x45 >;
			pinctrl-1 = < 0x46 >;
			clocks = < 0x02 0x47 >;
			pcm_lrck_period = < 0x20 >;
			pcm_lrckr_period = < 0x01 >;
			slot_width_select = < 0x20 >;
			pcm_lsb_first = < 0x00 >;
			tx_data_mode = < 0x00 >;
			rx_data_mode = < 0x00 >;
			daudio_master = < 0x04 >;
			audio_format = < 0x01 >;
			signal_inversion = < 0x01 >;
			frametype = < 0x00 >;
			tdm_config = < 0x01 >;
			tdm_num = < 0x01 >;
			status = "disabled";
			linux,phandle = < 0x4f >;
			phandle = < 0x4f >;
			device_type = "daudio1";
		};

		daudio@0x01c22800 {
			compatible = "allwinner,sunxi-tdmhdmi";
			reg = < 0x00 0x1c22800 0x00 0x58 >;
			clocks = < 0x02 0x48 >;
			status = "okay";
			linux,phandle = < 0x50 >;
			phandle = < 0x50 >;
			device_type = "daudio2";
		};

		spdif-controller@0x01c21000 {
			compatible = "allwinner,sunxi-spdif";
			reg = < 0x00 0x1c21000 0x00 0x38 >;
			clocks = < 0x02 0x49 >;
			pinctrl-names = "default\0sleep";
			pinctrl-0 = < 0x4a >;
			pinctrl-1 = < 0x4b >;
			status = "disabled";
			linux,phandle = < 0x51 >;
			phandle = < 0x51 >;
			device_type = "spdif";
		};

		sound@0 {
			compatible = "allwinner,sunxi-codec-machine";
			interrupts = < 0x00 0x1c 0x04 >;
			sunxi,i2s-controller = < 0x4c >;
			sunxi,audio-codec = < 0x4d >;
			aif2fmt = < 0x03 >;
			aif3fmt = < 0x03 >;
			aif2master = < 0x01 >;
			hp_detect_case = < 0x01 >;
			status = "okay";
			device_type = "sndcodec";
		};

		sound@1 {
			compatible = "allwinner,sunxi-daudio0-machine";
			sunxi,daudio0-controller = < 0x4e >;
			status = "disabled";
			device_type = "snddaudio0";
		};

		sound@2 {
			compatible = "allwinner,sunxi-daudio1-machine";
			sunxi,daudio1-controller = < 0x4f >;
			status = "disabled";
			device_type = "snddaudio1";
		};

		sound@3 {
			compatible = "allwinner,sunxi-hdmi-machine";
			sunxi,hdmi-controller = < 0x50 >;
			status = "okay";
			device_type = "sndhdmi";
		};

		sound@4 {
			compatible = "allwinner,sunxi-spdif-machine";
			sunxi,spdif-controller = < 0x51 >;
			status = "disabled";
			device_type = "sndspdif";
		};

		spi@01c68000 {
			#address-cells = < 0x01 >;
			#size-cells = < 0x00 >;
			compatible = "allwinner,sun50i-spi";
			device_type = "spi0";
			reg = < 0x00 0x1c68000 0x00 0x1000 >;
			interrupts = < 0x00 0x41 0x04 >;
			clocks = < 0x04 0x52 >;
			clock-frequency = < 0x5f5e100 >;
			pinctrl-names = "default\0sleep";
			spi0_cs_number = < 0x01 >;
			spi0_cs_bitmap = < 0x01 >;
			status = "disabled";
			pinctrl-0 = < 0xaf 0xb0 >;
			pinctrl-1 = < 0xb1 0xb2 >;
		};

		spi@01c69000 {
			#address-cells = < 0x01 >;
			#size-cells = < 0x00 >;
			compatible = "allwinner,sun50i-spi";
			device_type = "spi1";
			reg = < 0x00 0x1c69000 0x00 0x1000 >;
			interrupts = < 0x00 0x42 0x04 >;
			clocks = < 0x04 0x56 >;
			clock-frequency = < 0x5f5e100 >;
			pinctrl-names = "default\0sleep";
			spi1_cs_number = < 0x01 >;
			spi1_cs_bitmap = < 0x01 >;
			status = "disabled";
			pinctrl-0 = < 0xb3 0xb4 >;
			pinctrl-1 = < 0xb5 0xb6 >;
		};

		sdmmc@01C11000 {
			compatible = "allwinner,sun50i-sdmmc2";
			device_type = "sdc2";
			reg = < 0x00 0x1c11000 0x00 0x1000 >;
			interrupts = < 0x00 0x3e 0x104 >;
			clocks = < 0x06 0x5a 0x5b 0x5c 0x5d >;
			clock-names = "osc24m\0pll_periph\0mmc\0ahb\0rst";
			pinctrl-names = "default\0sleep";
			pinctrl-1 = < 0x5f >;
			bus-width = < 0x08 >;
			max-frequency = < 0x5f5e100 >;
			sdc_tm4_sm0_freq0 = < 0x00 >;
			sdc_tm4_sm0_freq1 = < 0x00 >;
			sdc_tm4_sm1_freq0 = < 0x00 >;
			sdc_tm4_sm1_freq1 = < 0x00 >;
			sdc_tm4_sm2_freq0 = < 0x00 >;
			sdc_tm4_sm2_freq1 = < 0x00 >;
			sdc_tm4_sm3_freq0 = < 0x5000000 >;
			sdc_tm4_sm3_freq1 = < 0x405 >;
			sdc_tm4_sm4_freq0 = < 0x50000 >;
			sdc_tm4_sm4_freq1 = < 0x408 >;
			status = "okay";
			non-removable;
			pinctrl-0 = < 0xc2 >;
			cd-gpios;
			sunxi-power-save-mode;
			sunxi-dis-signal-vol-sw;
			mmc-ddr-1_8v;
			mmc-hs200-1_8v;
			mmc-hs400-1_8v;
			vmmc = "vcc-emmcv";
			vqmmc = "vcc-emmcvq18";
			vdmmc = "none";
		};

		sdmmc@01c0f000 {
			compatible = "allwinner,sun50i-sdmmc0";
			device_type = "sdc0";
			reg = < 0x00 0x1c0f000 0x00 0x1000 >;
			interrupts = < 0x00 0x3c 0x104 >;
			clocks = < 0x06 0x5a 0x60 0x61 0x62 >;
			clock-names = "osc24m\0pll_periph\0mmc\0ahb\0rst";
			pinctrl-names = "default\0sleep";
			pinctrl-1 = < 0x64 >;
			max-frequency = < 0x2faf080 >;
			bus-width = < 0x04 >;
			broken-cd;
			status = "okay";
			pinctrl-0 = < 0xc0 >;
			cd-gpios = < 0x30 0x05 0x06 0x00 0x01 0x02 0xffffffff >;
			sunxi-power-save-mode;
			vmmc = "vcc-sdcv";
			vqmmc = "vcc-sdcvq33";
			vdmmc = "vcc-sdc";
		};

		sdmmc@1C10000 {
			compatible = "allwinner,sun50i-sdmmc1";
			device_type = "sdc1";
			reg = < 0x00 0x1c10000 0x00 0x1000 >;
			interrupts = < 0x00 0x3d 0x104 >;
			clocks = < 0x06 0x5a 0x65 0x66 0x67 >;
			clock-names = "osc24m\0pll_periph\0mmc\0ahb\0rst";
			pinctrl-names = "default\0sleep";
			pinctrl-1 = < 0x69 >;
			max-frequency = < 0x8f0d180 >;
			bus-width = < 0x04 >;
			sunxi-dly-52M-ddr4 = < 0x01 0x00 0x00 0x00 0x02 >;
			sunxi-dly-104M = < 0x01 0x00 0x00 0x00 0x01 >;
			sunxi-dly-208M = < 0x01 0x00 0x00 0x00 0x01 >;
			status = "okay";
			pinctrl-0 = < 0xc1 >;
			sd-uhs-sdr50;
			sd-uhs-ddr50;
			sd-uhs-sdr104;
			cap-sdio-irq;
			keep-power-in-suspend;
			ignore-pm-notify;
		};

		disp@01000000 {
			compatible = "allwinner,sun50i-disp";
			reg = < 0x00 0x1000000 0x00 0x300000 0x00 0x1c0c000 0x00 0x7fc 0x00 0x1c0d000 0x00 0x7fc 0x00 0x1ca0000 0x00 0x10fc >;
			interrupts = < 0x00 0x56 0x104 0x00 0x57 0x104 0x00 0x59 0x104 >;
			clocks = < 0x6a 0x6b 0x6c 0x6d 0x6e >;
			status = "okay";
			device_type = "disp";
			disp_init_enable = < 0x01 >;
			disp_mode = < 0x00 >;
			screen0_output_type = < 0x01 >;
			screen0_output_mode = < 0x04 >;
			screen1_output_type = < 0x03 >;
			screen1_output_mode = < 0x04 >;
			fb0_format = < 0x00 >;
			fb0_width = < 0x00 >;
			fb0_height = < 0x00 >;
			fb1_format = < 0x00 >;
			fb1_width = < 0x00 >;
			fb1_height = < 0x00 >;
		};

		lcd0@01c0c000 {
			compatible = "allwinner,sunxi-lcd0";
			pinctrl-names = "active\0sleep";
			status = "okay";
			device_type = "lcd0";
			lcd_used = < 0x01 >;
			lcd_driver_name = "anx9804_panel";
			lcd_model_name = < 0x02 >;
			lcd_backlight = < 0x32 >;
			lcd_if = < 3 >;
			lcd_x = < 1920 >;
			lcd_y = < 1080 >;
			lcd_width = < 0x100 >;
			lcd_height = < 0x90 >;
			lcd_dclk_freq = < 139 >;
			lcd_pwm_used = < 0x01 >;
			lcd_pwm_ch = < 0x00 >;
			lcd_pwm_freq = < 0xc8 >;
			lcd_pwm_pol = < 0x00 >;
			lcd_pwm_max_limit = < 0xfa >;
			lcd_hbp = < 112 >;
			lcd_ht = < 2080 >;
			lcd_hspw = < 32 >;
			lcd_vbp = < 28 >;
			lcd_vt = < 1111 >;
			lcd_vspw = < 5 >;
			lcd_lvds_if = < 0x00 >;
			lcd_lvds_colordepth = < 0x00 >;
			lcd_lvds_mode = < 0x00 >;
			lcd_frm = < 0x01 >;
			lcd_hv_clk_phase = < 0x00 >;
			lcd_hv_sync_polarity = < 0x00 >;
			lcd_dsi_if = < 0x00 >;
			lcd_dsi_lane = < 0x04 >;
			lcd_dsi_format = < 0x00 >;
			lcd_dsi_te = < 0x00 >;
			lcd_gamma_en = < 0x00 >;
			lcd_bright_curve_en = < 0x00 >;
			lcd_cmap_en = < 0x00 >;
			lcd_edp_tx_rate = < 0x02 >;
			lcd_edp_tx_lane = < 0x02 >;
			lcd_edp_colordepth = < 0x01 >;
			lcdgamma4iep = < 0x16 >;
			lcd_bl_en = < 0x30 0x03 0x17 0x01 0x00 0xffffffff 0x01 >;
			lcd_bl_en_power = "none";
			lcd_power = "vcc-lvds";
			lcd_power1 = "vcc-mipi";
			lcd_power2 = "vcc-hsic-12";
			lcd_gpio_0 = < 0x30 0x03 0x18 0x01 0x00 0xffffffff 0x00 >;
			lcd_gpio_1 = < 0x30 0x07 0x06 0x01 0x00 0xffffffff 0x01 >;
			pinctrl-0 = < 0xb9 >;
			lcd_pin_power = "vcc-pd";
			pinctrl-1 = < 0xba >;
		};

		hdmi@01ee0000 {
			compatible = "allwinner,sunxi-hdmi";
			reg = < 0x00 0x1ee0000 0x00 0x20000 >;
			clocks = < 0x6f 0x70 >;
			device_type = "hdmi";
			status = "okay";
			hdmi_power = "vcc-hdmi-33";
			hdmi_hdcp_enable = < 0x00 >;
			hdmi_cts_compatibility = < 0x00 >;
		};

		tr@01000000 {
			compatible = "allwinner,sun50i-tr";
			reg = < 0x00 0x1000000 0x00 0x200bc >;
			interrupts = < 0x00 0x60 0x104 >;
			clocks = < 0x6a >;
			status = "okay";
		};

		pwm@01c21400 {
			compatible = "allwinner,sunxi-pwm";
			reg = < 0x00 0x1c21400 0x00 0x3c >;
			pwm-number = < 0x01 >;
			pwm-base = < 0x00 >;
			pwms = < 0x71 >;
		};

		pwm0@01c21400 {
			compatible = "allwinner,sunxi-pwm0";
			pinctrl-names = "active\0sleep";
			reg_base = < 0x1c21400 >;
			reg_busy_offset = < 0x00 >;
			reg_busy_shift = < 0x1c >;
			reg_enable_offset = < 0x00 >;
			reg_enable_shift = < 0x04 >;
			reg_clk_gating_offset = < 0x00 >;
			reg_clk_gating_shift = < 0x06 >;
			reg_bypass_offset = < 0x00 >;
			reg_bypass_shift = < 0x09 >;
			reg_pulse_start_offset = < 0x00 >;
			reg_pulse_start_shift = < 0x08 >;
			reg_mode_offset = < 0x00 >;
			reg_mode_shift = < 0x07 >;
			reg_polarity_offset = < 0x00 >;
			reg_polarity_shift = < 0x05 >;
			reg_period_offset = < 0x04 >;
			reg_period_shift = < 0x10 >;
			reg_period_width = < 0x10 >;
			reg_active_offset = < 0x04 >;
			reg_active_shift = < 0x00 >;
			reg_active_width = < 0x10 >;
			reg_prescal_offset = < 0x00 >;
			reg_prescal_shift = < 0x00 >;
			reg_prescal_width = < 0x04 >;
			linux,phandle = < 0x71 >;
			phandle = < 0x71 >;
			device_type = "pwm0";
			pwm_used = < 0x01 >;
			pinctrl-0 = < 0xbb >;
			pinctrl-1 = < 0xbc >;
		};

		s_pwm@1f03800 {
			compatible = "allwinner,sunxi-s_pwm";
			reg = < 0x00 0x1f03800 0x00 0x3c >;
			pwm-number = < 0x01 >;
			pwm-base = < 0x10 >;
			pwms = < 0x72 >;
		};

		spwm0@0x01f03800 {
			compatible = "allwinner,sunxi-pwm16";
			pinctrl-names = "active\0sleep";
			reg_base = < 0x1f03800 >;
			reg_busy_offset = < 0x00 >;
			reg_busy_shift = < 0x1c >;
			reg_enable_offset = < 0x00 >;
			reg_enable_shift = < 0x04 >;
			reg_clk_gating_offset = < 0x00 >;
			reg_clk_gating_shift = < 0x06 >;
			reg_bypass_offset = < 0x00 >;
			reg_bypass_shift = < 0x09 >;
			reg_pulse_start_offset = < 0x00 >;
			reg_pulse_start_shift = < 0x08 >;
			reg_mode_offset = < 0x00 >;
			reg_mode_shift = < 0x07 >;
			reg_polarity_offset = < 0x00 >;
			reg_polarity_shift = < 0x05 >;
			reg_period_offset = < 0x04 >;
			reg_period_shift = < 0x10 >;
			reg_period_width = < 0x10 >;
			reg_active_offset = < 0x04 >;
			reg_active_shift = < 0x00 >;
			reg_active_width = < 0x10 >;
			reg_prescal_offset = < 0x00 >;
			reg_prescal_shift = < 0x00 >;
			reg_prescal_width = < 0x04 >;
			linux,phandle = < 0x72 >;
			phandle = < 0x72 >;
		};

		boot_disp {
			compatible = "allwinner,boot_disp";
			device_type = "boot_disp";
			output_disp = < 0x00 >;
			output_type = < 0x01 >;
			output_mode = < 0x04 >;
		};

		cci@0x01cb3000 {
			compatible = "allwinner,sunxi-csi_cci";
			reg = < 0x00 0x1cb3000 0x00 0x1000 >;
			interrupts = < 0x00 0x55 0x04 >;
			status = "okay";
		};

		csi_res@0x01cb0000 {
			compatible = "allwinner,sunxi-csi";
			reg = < 0x00 0x1cb0000 0x00 0x1000 >;
			status = "okay";
		};

		vfe@0 {
			device_type = "csi0";
			compatible = "allwinner,sunxi-vfe";
			interrupts = < 0x00 0x54 0x04 >;
			clocks = < 0x73 0x74 0x75 0x04 0x06 0x05 >;
			pinctrl-names = "default\0sleep";
			pinctrl-1 = < 0x77 >;
			csi0_sensor_list = < 0x00 >;
			status = "okay";
			pinctrl-0 = < 0xbf >;
			csi0_mck = < 0x30 0x04 0x01 0x00 0x00 0x01 0x00 >;

			dev@0 {
				csi0_dev0_mname = "bf3703";
				csi0_dev0_twi_addr = < 0x3e >;
				csi0_dev0_pos = "rear";
				csi0_dev0_isp_used = < 0x01 >;
				csi0_dev0_fmt = < 0x00 >;
				csi0_dev0_stby_mode = < 0x01 >;
				csi0_dev0_vflip = < 0x00 >;
				csi0_dev0_hflip = < 0x00 >;
				csi0_dev0_iovdd = "iovdd-csi";
				csi0_dev0_iovdd_vol = < 0x2ab980 >;
				csi0_dev0_avdd = "avdd-csi";
				csi0_dev0_avdd_vol = < 0x2ab980 >;
				csi0_dev0_dvdd = "dvdd-csi-18";
				csi0_dev0_dvdd_vol = < 0x1b7740 >;
				csi0_dev0_flash_used = < 0x00 >;
				csi0_dev0_flash_type = < 0x02 >;
				csi0_dev0_flvdd = "vdd-csi-led";
				csi0_dev0_flvdd_vol = < 0x325aa0 >;
				csi0_dev0_act_used = < 0x00 >;
				csi0_dev0_act_name = "ad5820_act";
				csi0_dev0_act_slave = < 0x18 >;
				status = "okay";
				device_type = "csi0_dev0";
				csi0_dev0_afvdd;
				csi0_dev0_afvdd_vol;
				csi0_dev0_power_en;
				csi0_dev0_reset = < 0x30 0x04 0x0e 0x00 0x00 0x01 0x00 >;
				csi0_dev0_pwdn = < 0x30 0x04 0x0f 0x00 0x00 0x01 0x00 >;
				csi0_dev0_flash_en;
				csi0_dev0_flash_mode;
				csi0_dev0_af_pwdn;
			};

			dev@1 {
				csi0_dev1_mname = "gc2145";
				csi0_dev1_twi_addr = < 0x78 >;
				csi0_dev1_pos = "front";
				csi0_dev1_isp_used = < 0x01 >;
				csi0_dev1_fmt = < 0x00 >;
				csi0_dev1_stby_mode = < 0x01 >;
				csi0_dev1_vflip = < 0x00 >;
				csi0_dev1_hflip = < 0x00 >;
				csi0_dev1_iovdd = "iovdd-csi";
				csi0_dev1_iovdd_vol = < 0x2ab980 >;
				csi0_dev1_avdd = "avdd-csi";
				csi0_dev1_avdd_vol = < 0x2ab980 >;
				csi0_dev1_dvdd = "dvdd-csi-18";
				csi0_dev1_dvdd_vol = < 0x1b7740 >;
				csi0_dev1_flash_used = < 0x00 >;
				csi0_dev1_flash_type = < 0x02 >;
				csi0_dev1_flvdd = "vdd-csi-led";
				csi0_dev1_flvdd_vol = < 0x325aa0 >;
				csi0_dev1_act_used = < 0x00 >;
				csi0_dev1_act_name = "ad5820_act";
				csi0_dev1_act_slave = < 0x18 >;
				status = "disabled";
				device_type = "csi0_dev1";
				csi0_dev1_afvdd;
				csi0_dev1_afvdd_vol;
				csi0_dev1_power_en;
				csi0_dev1_reset = < 0x30 0x04 0x10 0x00 0x00 0x01 0x00 >;
				csi0_dev1_pwdn = < 0x30 0x04 0x11 0x00 0x00 0x01 0x00 >;
				csi0_dev1_flash_en;
				csi0_dev1_flash_mode;
				csi0_dev1_af_pwdn;
			};
		};

		vdevice@0 {
			compatible = "allwinner,sun50i-vdevice";
			pinctrl-names = "default";
			test-gpios = < 0x79 0x0b 0x00 0x01 0x02 0x03 0x04 >;
			status = "okay";
			device_type = "Vdevice";
			pinctrl-0 = < 0xc7 >;
		};

		ce@1c15000 {
			compatible = "allwinner,sunxi-ce";
			reg = < 0x00 0x1c15000 0x00 0x80 0x00 0x1c15800 0x00 0x80 >;
			interrupts = < 0x00 0x5e 0xff01 0x00 0x50 0xff01 >;
			clock-frequency = < 0x11e1a300 0xbebc200 >;
			clocks = < 0x7a 0x7b >;
		};

		deinterlace@0x01e00000 {
			#address-cells = < 0x01 >;
			#size-cells = < 0x00 >;
			compatible = "allwinner,sunxi-deinterlace";
			reg = < 0x00 0x1e00000 0x00 0x77c >;
			interrupts = < 0x00 0x5d 0x04 >;
			clocks = < 0x7c 0x04 >;
			status = "okay";
			device_type = "di";
		};

		smartcard@0x01c2c400 {
			#address-cells = < 0x01 >;
			#size-cells = < 0x00 >;
			compatible = "allwinner,sunxi-scr";
			reg = < 0x00 0x1c2c400 0x00 0x100 >;
			interrupts = < 0x00 0x53 0x04 >;
			clocks = < 0x7d 0x7e >;
			clock-frequency = < 0x16e3600 >;
			pinctrl-names = "default";
			pinctrl-0 = < 0x7f >;
			status = "okay";
			device_type = "smc";
			smc_used;
			smc_rst;
			smc_vppen;
			smc_vppp;
			smc_det;
			smc_vccen;
			smc_sck;
			smc_sda;
		};

		nmi@0x01f00c00 {
			#address-cells = < 0x01 >;
			#size-cells = < 0x00 >;
			compatible = "allwinner,sunxi-nmi";
			reg = < 0x00 0x1f00c00 0x00 0x50 >;
			nmi_irq_ctrl = < 0x0c >;
			nmi_irq_en = < 0x40 >;
			nmi_irq_status = < 0x10 >;
			nmi_irq_mask = < 0x50 >;
			status = "okay";
		};

		pmu0@0 {
			compatible = "allwinner,pmu0";
			device_type = "pmu0";
			pmu_batdeten = < 0x01 >;
			pmu_init_chgend_rate = < 0x14 >;
			pmu_init_chg_enabled = < 0x01 >;
			pmu_init_adc_freq = < 0x320 >;
			pmu_init_adcts_freq = < 0x320 >;
			pmu_init_chg_pretime = < 0x46 >;
			pmu_init_chg_csttime = < 0x2d0 >;
			pmu_batt_cap_correct = < 0x01 >;
			pmu_chg_end_on_en = < 0x00 >;
			pmu_pwroff_vol = < 0xce4 >;
			pmu_pwron_vol = < 0xa28 >;
			pmu_powkey_off_delay_time = < 0x00 >;
			pmu_pwrok_time = < 0x40 >;
			pmu_reset_shutdown_en = < 0x01 >;
			pmu_restvol_adjust_time = < 0x3c >;
			pmu_ocv_cou_adjust_time = < 0x3c >;
			pmu_vbusen_func = < 0x01 >;
			pmu_reset = < 0x00 >;
			pmu_IRQ_wakeup = < 0x01 >;
			pmu_hot_shutdowm = < 0x01 >;
			pmu_inshort = < 0x00 >;
			pmu_bat_shutdown_ltf = < 0xc80 >;
			pmu_bat_shutdown_htf = < 0xed >;
			status = "okay";
			pmu_id = < 0x06 >;
			pmu_twi_addr = < 0x34 >;
			pmu_twi_id = < 0x01 >;
			pmu_irq_id = < 0x40 >;
			pmu_chg_ic_temp = < 0x00 >;
			pmu_battery_rdc = < 0x45 >;
			pmu_battery_cap = < 0x2463 >;
			pmu_runtime_chgcur = < 0x708 >;
			pmu_suspend_chgcur = < 0x5dc >;
			pmu_shutdown_chgcur = < 0x5dc >;
			pmu_init_chgvol = < 0x1068 >;
			pmu_ac_vol = < 0xfa0 >;
			pmu_ac_cur = < 0xdac >;
			pmu_usbpc_vol = < 0x1130 >;
			pmu_usbpc_cur = < 0x1f4 >;
			pmu_battery_warning_level1 = < 0x0f >;
			pmu_battery_warning_level2 = < 0x00 >;
			pmu_chgled_func = < 0x01 >;
			pmu_chgled_type = < 0x00 >;
			pmu_bat_para1 = < 0x00 >;
			pmu_bat_para2 = < 0x00 >;
			pmu_bat_para3 = < 0x00 >;
			pmu_bat_para4 = < 0x00 >;
			pmu_bat_para5 = < 0x00 >;
			pmu_bat_para6 = < 0x00 >;
			pmu_bat_para7 = < 0x04 >;
			pmu_bat_para8 = < 0x07 >;
			pmu_bat_para9 = < 0x09 >;
			pmu_bat_para10 = < 0x0c >;
			pmu_bat_para11 = < 0x0d >;
			pmu_bat_para12 = < 0x11 >;
			pmu_bat_para13 = < 0x15 >;
			pmu_bat_para14 = < 0x1b >;
			pmu_bat_para15 = < 0x30 >;
			pmu_bat_para16 = < 0x34 >;
			pmu_bat_para17 = < 0x37 >;
			pmu_bat_para18 = < 0x3a >;
			pmu_bat_para19 = < 0x3d >;
			pmu_bat_para20 = < 0x42 >;
			pmu_bat_para21 = < 0x47 >;
			pmu_bat_para22 = < 0x4c >;
			pmu_bat_para23 = < 0x51 >;
			pmu_bat_para24 = < 0x54 >;
			pmu_bat_para25 = < 0x5a >;
			pmu_bat_para26 = < 0x5f >;
			pmu_bat_para27 = < 0x62 >;
			pmu_bat_para28 = < 0x64 >;
			pmu_bat_para29 = < 0x64 >;
			pmu_bat_para30 = < 0x64 >;
			pmu_bat_para31 = < 0x64 >;
			pmu_bat_para32 = < 0x64 >;
			pmu_bat_temp_enable = < 0x00 >;
			pmu_bat_charge_ltf = < 0x8d5 >;
			pmu_bat_charge_htf = < 0x184 >;
			pmu_bat_temp_para1 = < 0x1d2a >;
			pmu_bat_temp_para2 = < 0x1180 >;
			pmu_bat_temp_para3 = < 0xdbe >;
			pmu_bat_temp_para4 = < 0xae2 >;
			pmu_bat_temp_para5 = < 0x8af >;
			pmu_bat_temp_para6 = < 0x6fc >;
			pmu_bat_temp_para7 = < 0x5a8 >;
			pmu_bat_temp_para8 = < 0x3c9 >;
			pmu_bat_temp_para9 = < 0x298 >;
			pmu_bat_temp_para10 = < 0x1d2 >;
			pmu_bat_temp_para11 = < 0x189 >;
			pmu_bat_temp_para12 = < 0x14d >;
			pmu_bat_temp_para13 = < 0x11b >;
			pmu_bat_temp_para14 = < 0xf2 >;
			pmu_bat_temp_para15 = < 0xb3 >;
			pmu_bat_temp_para16 = < 0x86 >;
			pmu_powkey_off_time = < 0x1770 >;
			pmu_powkey_off_func = < 0x00 >;
			pmu_powkey_off_en = < 0x01 >;
			pmu_powkey_long_time = < 0x5dc >;
			pmu_powkey_on_time = < 0x3e8 >;
			power_start = < 0x00 >;
		};

		regu@0 {
			compatible = "allwinner,pmu0_regu";
			regulator_count = < 0x17 >;
			status = "okay";
			device_type = "pmu0_regu";
			regulator1 = "axp81x_dcdc1 none vcc-nand vcc-emmc vcc-sdc vcc-usb-30 vcc-io vcc-pd";
			regulator2 = "axp81x_dcdc2 none vdd-cpua";
			regulator3 = "axp81x_dcdc3 none";
			regulator4 = "axp81x_dcdc4 none";
			regulator5 = "axp81x_dcdc5 none vcc-dram";
			regulator6 = "axp81x_dcdc6 none vdd-sys";
			regulator7 = "axp81x_dcdc7 none";
			regulator8 = "axp81x_rtc none";
			regulator9 = "axp81x_aldo1 none vdd-csi-led iovdd-csi vcc-pe";
			regulator10 = "axp81x_aldo2 none vcc-pl";
			regulator11 = "axp81x_aldo3 none vcc-avcc vcc-pll";
			regulator12 = "axp81x_dldo1 none vcc-hdmi-33 vcc-dsi-33 vcc-sensor";
			regulator13 = "axp81x_dldo2 none vcc-mipi";
			regulator14 = "axp81x_dldo3 none avdd-csi";
			regulator15 = "axp81x_dldo4 none vcc-wifi-io";
			regulator16 = "axp81x_eldo1 none vcc-cpvdd vcc-pc vcc-pg";
			regulator17 = "axp81x_eldo2 none vcc-lcd-0 hall-vcc-18";
			regulator18 = "axp81x_eldo3 none dvdd-csi-18";
			regulator19 = "axp81x_fldo1 none vcc-hsic-12";
			regulator20 = "axp81x_fldo2 none vdd-cpus";
			regulator21 = "axp81x_gpio0ldo none vcc-ctp";
			regulator22 = "axp81x_gpio1ldo none";
			regulator23 = "axp81x_dc1sw none vcc-lvds";
		};

		nand0@01c03000 {
			compatible = "allwinner,sun50i-nand";
			device_type = "nand0";
			reg = < 0x00 0x1c03000 0x00 0x1000 >;
			interrupts = < 0x00 0x46 0x04 >;
			clocks = < 0x04 0x80 >;
			pinctrl-names = "default\0sleep";
			pinctrl-1 = < 0x83 >;
			nand0_regulator1 = "vcc-nand";
			nand0_regulator2 = "none";
			nand0_cache_level = < 0x55aaaa55 >;
			nand0_flush_cache_num = < 0x55aaaa55 >;
			nand0_capacity_level = < 0x55aaaa55 >;
			nand0_id_number_ctl = < 0x55aaaa55 >;
			nand0_print_level = < 0x55aaaa55 >;
			nand0_p0 = < 0x55aaaa55 >;
			nand0_p1 = < 0x55aaaa55 >;
			nand0_p2 = < 0x55aaaa55 >;
			nand0_p3 = < 0x55aaaa55 >;
			status = "okay";
			nand0_dragonboard = < 0x00 >;
			nand0_support_2ch = < 0x00 >;
			pinctrl-0 = < 0xb7 0xb8 >;
		};

		thermal_sensor {
			compatible = "allwinner,thermal_sensor";
			reg = < 0x00 0x1c25000 0x00 0x400 >;
			interrupts = < 0x00 0x1f 0x00 >;
			clocks = < 0x06 0x84 >;
			sensor_num = < 0x03 >;
			shut_temp = < 0x78 >;
			status = "okay";

			combine0 {
				#thermal-sensor-cells = < 0x01 >;
				combine_cnt = < 0x03 >;
				combine_type = "max";
				combine_chn = < 0x00 0x01 0x02 >;
				linux,phandle = < 0x85 >;
				phandle = < 0x85 >;
			};
		};

		cpu_budget_cool {
			compatible = "allwinner,budget_cooling";
			#cooling-cells = < 0x02 >;
			status = "okay";
			state_cnt = < 0x0a >;
			cluster_num = < 0x01 >;
			state0 = < 0x119400 0x04 >;
			state1 = < 0x10d880 0x04 >;
			state2 = < 0x101d00 0x04 >;
			state3 = < 0xf6180 0x04 >;
			state4 = < 0xea600 0x04 >;
			state5 = < 0xdea80 0x04 >;
			state6 = < 0xc7380 0x04 >;
			state7 = < 0x9e340 0x04 >;
			state8 = < 0x9e340 0x02 >;
			state9 = < 0x9e340 0x01 >;
			linux,phandle = < 0x87 >;
			phandle = < 0x87 >;
		};

		gpu_cooling {
			compatible = "allwinner,gpu_cooling";
			reg = < 0x00 0x00 0x00 0x00 >;
			#cooling-cells = < 0x02 >;
			status = "okay";
			state_cnt = < 0x03 >;
			state0 = < 0x00 >;
			state1 = < 0x168 >;
			state2 = < 0x90 >;
			linux,phandle = < 0x8c >;
			phandle = < 0x8c >;
		};

		thermal-zones {

			soc_thermal {
				polling-delay-passive = < 0x1f4 >;
				polling-delay = < 0x7d0 >;
				thermal-sensors = < 0x85 0x00 >;

				trips {

					t0 {
						temperature = < 0x50 >;
						type = "passive";
						hysteresis = < 0x00 >;
						linux,phandle = < 0x86 >;
						phandle = < 0x86 >;
					};

					t1 {
						temperature = < 0x55 >;
						type = "passive";
						hysteresis = < 0x00 >;
						linux,phandle = < 0x88 >;
						phandle = < 0x88 >;
					};

					t2 {
						temperature = < 0x5a >;
						type = "passive";
						hysteresis = < 0x00 >;
						linux,phandle = < 0x89 >;
						phandle = < 0x89 >;
					};

					t3 {
						temperature = < 0x5f >;
						type = "passive";
						hysteresis = < 0x00 >;
						linux,phandle = < 0x8a >;
						phandle = < 0x8a >;
					};

					t4 {
						temperature = < 0x55 >;
						type = "passive";
						hysteresis = < 0x00 >;
						linux,phandle = < 0x8b >;
						phandle = < 0x8b >;
					};

					t5 {
						temperature = < 0x5f >;
						type = "passive";
						hysteresis = < 0x00 >;
						linux,phandle = < 0x8d >;
						phandle = < 0x8d >;
					};

					t6 {
						temperature = < 0x6e >;
						type = "critical";
						hysteresis = < 0x00 >;
					};
				};

				cooling-maps {

					bind0 {
						contribution = < 0x00 >;
						trip = < 0x86 >;
						cooling-device = < 0x87 0x01 0x01 >;
					};

					bind1 {
						contribution = < 0x00 >;
						trip = < 0x88 >;
						cooling-device = < 0x87 0x02 0x02 >;
					};

					bind2 {
						contribution = < 0x00 >;
						trip = < 0x89 >;
						cooling-device = < 0x87 0x03 0x06 >;
					};

					bind3 {
						contribution = < 0x00 >;
						trip = < 0x8a >;
						cooling-device = < 0x87 0x07 0x09 >;
					};

					bind4 {
						contribution = < 0x00 >;
						trip = < 0x8b >;
						cooling-device = < 0x8c 0x01 0x01 >;
					};

					bind5 {
						contribution = < 0x00 >;
						trip = < 0x8d >;
						cooling-device = < 0x8c 0x02 0x02 >;
					};
				};
			};
		};

		keyboard {
			compatible = "allwinner,keyboard_2000mv";
			reg = < 0x00 0x1c21800 0x00 0x400 >;
			interrupts = < 0x00 0x1e 0x00 >;
			status = "okay";
			key_cnt = < 0x05 >;
			key1 = < 0xf0 0x73 >;
			key2 = < 0x1f4 0x72 >;
			key3 = < 0x2bc 0x8b >;
			key4 = < 0x37a 0x1c >;
			key5 = < 0x7d0 0x66 >;
		};

		eth@01c30000 {
			compatible = "allwinner,sunxi-gmac";
			reg = < 0x00 0x1c30000 0x00 0x40000 0x00 0x1c00000 0x00 0x30 >;
			pinctrl-names = "default";
			pinctrl-0 = < 0x8e >;
			interrupts = < 0x00 0x52 0x04 >;
			interrupt-names = "gmacirq";
			clocks = < 0x8f >;
			clock-names = "gmac";
			phy-mode = "rgmii";
			tx-delay = < 0x07 >;
			rx-delay = < 0x1f >;
			gmac_power1 = "axp81x_dldo2:2500000";
			gmac_power2 = "axp81x_eldo2:1800000";
			gmac_power3 = "axp81x_fldo1:1200000";
			status = "disable";
		};

		product {
			device_type = "product";
			version = "100";
			machine = "evb";
		};

		platform {
			device_type = "platform";
			eraseflag = < 0x01 >;
			next_work = < 0x03 >;
			debug_mode = < 0x00 >;
		};

		target {
			device_type = "target";
			boot_clock = < 0x3f0 >;
			storage_type = < 0xffffffff >;
			burn_key = < 0x01 >;
			dragonboard_test = < 0x00 >;
		};

		power_sply {
			device_type = "power_sply";
			dcdc1_vol = < 0xf4f24 >;
			dcdc6_vol = < 0xf468c >;
			aldo1_vol = < 0xaf0 >;
			aldo2_vol = < 0xf4948 >;
			aldo3_vol = < 0xf4df8 >;
			dldo1_vol = < 0xce4 >;
			dldo2_vol = < 0x9c4 >;
			dldo3_vol = < 0xaf0 >;
			dldo4_vol = < 0xf4f24 >;
			eldo1_vol = < 0xf4948 >;
			eldo2_vol = < 0x708 >;
			eldo3_vol = < 0x708 >;
			fldo1_vol = < 0x4b0 >;
			fldo2_vol = < 0xf468c >;
			gpio0_vol = < 0xf4e5c >;
		};

		card_boot {
			device_type = "card_boot";
			logical_start = < 0xa000 >;
			sprite_gpio0;
		};

		pm_para {
			device_type = "pm_para";
			standby_mode = < 0x01 >;
		};

		card0_boot_para {
			device_type = "card0_boot_para";
			card_ctrl = < 0x00 >;
			card_high_speed = < 0x01 >;
			card_line = < 0x04 >;
			pinctrl-0 = < 0x99 >;
		};

		card2_boot_para {
			device_type = "card2_boot_para";
			sdc_io_1v8 = < 0x01 >;
			card_ctrl = < 0x02 >;
			card_high_speed = < 0x01 >;
			card_line = < 0x08 >;
			pinctrl-0 = < 0x9a >;
			sdc_ex_dly_used = < 0x02 >;
		};

		twi_para {
			device_type = "twi_para";
			twi_port = < 0x00 >;
			pinctrl-0 = < 0x9b >;
		};

		uart_para {
			device_type = "uart_para";
			uart_debug_port = < 0x00 >;
			pinctrl-0 = < 0x9c >;
		};

		jtag_para {
			device_type = "jtag_para";
			jtag_enable = < 0x00 >;
			pinctrl-0 = < 0x9d >;
		};

		clock {
			device_type = "clock";
			pll4 = < 0x12c >;
			pll6 = < 0x258 >;
			pll8 = < 0x168 >;
			pll9 = < 0x129 >;
			pll10 = < 0x108 >;
		};

		gmac_para {
			device_type = "gmac_para";
			gmac_used = < 0x00 >;
			pinctrl-0 = < 0x9e >;
		};

		rtp_para {
			device_type = "rtp_para";
			rtp_used = < 0x00 >;
			rtp_screen_size = < 0x05 >;
			rtp_regidity_level = < 0x05 >;
			rtp_press_threshold_enable = < 0x00 >;
			rtp_press_threshold = < 0x1f40 >;
			rtp_sensitive_level = < 0x0f >;
			rtp_exchange_x_y_flag = < 0x00 >;
		};

		tkey_para {
			device_type = "tkey_para";
			tkey_used = < 0x00 >;
			tkey_twi_id;
			tkey_twi_addr;
			tkey_int;
		};

		motor_para {
			device_type = "motor_para";
			motor_used = < 0x00 >;
			motor_shake = < 0x31 0xfffe 0x03 0x01 0xffffffff 0xffffffff 0x01 >;
		};

		pwm16 {
			device_type = "pwm16";
			s_pwm0_used = < 0x00 >;
			pinctrl-0 = < 0xbd >;
			pinctrl-1 = < 0xbe >;
		};

		tvout_para {
			device_type = "tvout_para";
			tvout_used;
			tvout_channel_num;
			tv_en;
		};

		tvin_para {
			device_type = "tvin_para";
			tvin_used;
			tvin_channel_num;
		};

		serial_feature {
			device_type = "serial_feature";
			sn_filename = "ULI/factory/snum.txt";
		};

		gsensor_list {
			device_type = "gsensor_list";
		};

		3g_para {
			device_type = "3g_para";
			3g_used = < 0x00 >;
			3g_usbc_num = < 0x02 >;
			3g_uart_num = < 0x00 >;
			bb_vbat = < 0x79 0x0b 0x03 0x01 0xffffffff 0xffffffff 0x00 >;
			bb_host_wake = < 0x79 0x0c 0x00 0x01 0xffffffff 0xffffffff 0x00 >;
			bb_on = < 0x79 0x0c 0x01 0x01 0xffffffff 0xffffffff 0x00 >;
			bb_pwr_on = < 0x79 0x0c 0x03 0x01 0xffffffff 0xffffffff 0x00 >;
			bb_wake = < 0x79 0x0c 0x04 0x01 0xffffffff 0xffffffff 0x00 >;
			bb_rf_dis = < 0x79 0x0c 0x05 0x01 0xffffffff 0xffffffff 0x00 >;
			bb_rst = < 0x79 0x0c 0x06 0x01 0xffffffff 0xffffffff 0x00 >;
			3g_int;
		};

		gyroscopesensor {
			device_type = "gyroscopesensor";
			compatible = "allwinner,sun50i-gyr_sensors-para";
			status = "disabled";
			gy_twi_id = < 0x02 >;
			gy_twi_addr = < 0x6a >;
			gy_int1 = < 0x30 0x00 0x0a 0x06 0x01 0xffffffff 0xffffffff >;
			gy_int2;
		};

		gy_list {
			device_type = "gy_list";
			compatible = "allwinner,sun50i-gyr_sensors-list-para";
			status = "disabled";
			lsm9ds0_gyr = < 0x01 >;
			l3gd20_gyr = < 0x00 >;
			bmg160_gyr = < 0x01 >;
		};

		lightsensor {
			device_type = "lightsensor";
			compatible = "allwinner,sun50i-lsensors-para";
			status = "disabled";
			ls_twi_id = < 0x02 >;
			ls_twi_addr = < 0x23 >;
			ls_int = < 0x30 0x00 0x0c 0x06 0x01 0xffffffff 0xffffffff >;
		};

		ls_list {
			device_type = "ls_list";
			compatible = "allwinner,sun50i-lsensors-list-para";
			status = "disabled";
			ltr_501als = < 0x01 >;
			jsa1212 = < 0x00 >;
			jsa1127 = < 0x01 >;
			stk3x1x = < 0x00 >;
		};

		compasssensor {
			device_type = "compasssensor";
			compatible = "allwinner,sun50i-compass-para";
			status = "disabled";
			compass_twi_id = < 0x02 >;
			compass_twi_addr = < 0x0d >;
			compass_int = < 0x30 0x00 0x0b 0x06 0x01 0xffffffff 0xffffffff >;
		};

		compass_list {
			device_type = "compass_list";
			compatible = "allwinner,sun50i-compass-list-para";
			status = "disabled";
			lsm9ds0 = < 0x01 >;
			lsm303d = < 0x00 >;
		};

		recovery_key {
			device_type = "recovery_key";
			key_max = < 0x0c >;
			key_min = < 0x0a >;
		};

		fastboot_key {
			device_type = "fastboot_key";
			key_max = < 0x06 >;
			key_min = < 0x04 >;
		};

		secure {
			device_type = "secure";
			dram_region_mbytes = < 0x40 >;
			drm_region_mbytes = < 0x40 >;
			drm_region_start_mbytes = < 0x00 >;
		};
	};

	aliases {
		serial0 = "/soc@01c00000/uart@01c28000";
		serial1 = "/soc@01c00000/uart@01c28400";
		serial2 = "/soc@01c00000/uart@01c28800";
		serial3 = "/soc@01c00000/uart@01c28c00";
		serial4 = "/soc@01c00000/uart@01c29000";
		twi0 = "/soc@01c00000/twi@0x01c2ac00";
		twi1 = "/soc@01c00000/twi@0x01c2b000";
		twi2 = "/soc@01c00000/twi@0x01c2b400";
		spi0 = "/soc@01c00000/spi@01c68000";
		spi1 = "/soc@01c00000/spi@01c69000";
		global_timer0 = "/soc@01c00000/timer@1c20c00";
		cci0 = "/soc@01c00000/cci@0x01cb3000";
		csi_res0 = "/soc@01c00000/csi_res@0x01cb0000";
		vfe0 = "/soc@01c00000/vfe@0";
		mmc0 = "/soc@01c00000/sdmmc@01c0f000";
		mmc2 = "/soc@01c00000/sdmmc@01C11000";
		nand0 = "/soc@01c00000/nand0@01c03000";
		disp = "/soc@01c00000/disp@01000000";
		lcd0 = "/soc@01c00000/lcd0@01c0c000";
		hdmi = "/soc@01c00000/hdmi@01ee0000";
		pwm = "/soc@01c00000/pwm@01c21400";
		pwm0 = "/soc@01c00000/pwm0@01c21400";
		s_pwm = "/soc@01c00000/s_pwm@1f03800";
		spwm0 = "/soc@01c00000/spwm0@0x01f03800";
		boot_disp = "/soc@01c00000/boot_disp";
	};

	chosen {
		bootargs = "earlyprintk=sunxi-uart,0x01c28000 loglevel=8 initcall_debug=1 console=ttyS0 init=/init";
		1,initrd-start = < 0x00 0x00 >;
		1,initrd-end = < 0x00 0x00 >;
	};

	cpus {
		#address-cells = < 0x02 >;
		#size-cells = < 0x00 >;

		cpu@0 {
			device_type = "cpu";
			compatible = "arm,cortex-a53\0arm,armv8";
			reg = < 0x00 0x00 >;
			enable-method = "psci";
			cpufreq_tbl = < 0x75300 0x927c0 0xafc80 0xc7380 0xdea80 0xea600 0xf6180 0x101d00 0x10d880 0x119400 0x124f80 0x148200 >;
			clock-latency = < 0x1e8480 >;
			clock-frequency = < 0x3c14dc00 >;
			cpu-idle-states = < 0x90 0x91 0x92 >;
		};

		cpu@1 {
			device_type = "cpu";
			compatible = "arm,cortex-a53\0arm,armv8";
			reg = < 0x00 0x01 >;
			enable-method = "psci";
			clock-frequency = < 0x3c14dc00 >;
			cpu-idle-states = < 0x90 0x91 0x92 >;
		};

		cpu@2 {
			device_type = "cpu";
			compatible = "arm,cortex-a53\0arm,armv8";
			reg = < 0x00 0x02 >;
			enable-method = "psci";
			clock-frequency = < 0x3c14dc00 >;
			cpu-idle-states = < 0x90 0x91 0x92 >;
		};

		cpu@3 {
			device_type = "cpu";
			compatible = "arm,cortex-a53\0arm,armv8";
			reg = < 0x00 0x03 >;
			enable-method = "psci";
			clock-frequency = < 0x3c14dc00 >;
			cpu-idle-states = < 0x90 0x91 0x92 >;
		};

		idle-states {
			entry-method = "arm,psci";

			cpu-sleep-0 {
				compatible = "arm,idle-state";
				arm,psci-suspend-param = < 0x10000 >;
				entry-latency-us = < 0x28 >;
				exit-latency-us = < 0x64 >;
				min-residency-us = < 0x96 >;
				linux,phandle = < 0x90 >;
				phandle = < 0x90 >;
			};

			cluster-sleep-0 {
				compatible = "arm,idle-state";
				arm,psci-suspend-param = < 0x1010000 >;
				entry-latency-us = < 0x1f4 >;
				exit-latency-us = < 0x3e8 >;
				min-residency-us = < 0x9c4 >;
				linux,phandle = < 0x91 >;
				phandle = < 0x91 >;
			};

			sys-sleep-0 {
				compatible = "arm,idle-state";
				arm,psci-suspend-param = < 0x2010000 >;
				entry-latency-us = < 0x3e8 >;
				exit-latency-us = < 0x7d0 >;
				min-residency-us = < 0x1194 >;
				linux,phandle = < 0x92 >;
				phandle = < 0x92 >;
			};
		};
	};

	psci {
		compatible = "arm,psci-0.2";
		method = "smc";
		psci_version = < 0x84000000 >;
		cpu_suspend = < 0xc4000001 >;
		cpu_off = < 0x84000002 >;
		cpu_on = < 0xc4000003 >;
		affinity_info = < 0xc4000004 >;
		migrate = < 0xc4000005 >;
		migrate_info_type = < 0x84000006 >;
		migrate_info_up_cpu = < 0xc4000007 >;
		system_off = < 0x84000008 >;
		system_reset = < 0x84000009 >;
	};

	n_brom {
		compatible = "allwinner,n-brom";
		reg = < 0x00 0x00 0x00 0xc000 >;
	};

	s_brom {
		compatible = "allwinner,s-brom";
		reg = < 0x00 0x00 0x00 0x10000 >;
	};

	sram_a1 {
		compatible = "allwinner,sram_a1";
		reg = < 0x00 0x10000 0x00 0x8000 >;
	};

	sram_a2 {
		compatible = "allwinner,sram_a2";
		reg = < 0x00 0x40000 0x00 0x14000 >;
	};

	prcm {
		compatible = "allwinner,prcm";
		reg = < 0x00 0x1f01400 0x00 0x400 >;
	};

	cpuscfg {
		compatible = "allwinner,cpuscfg";
		reg = < 0x00 0x1f01c00 0x00 0x400 >;
	};

	ion {
		compatible = "allwinner,sunxi-ion";

		system_contig {
			type = < 0x01 >;
		};

		cma {
			type = < 0x04 >;
		};

		system {
			type = < 0x00 >;
		};
	};

	dram {
		compatible = "allwinner,dram";
		clocks = < 0x93 0x94 >;
		clock-names = "pll_ddr0\0pll_ddr1";
		dram_clk = < 0x228 >;
		dram_type = < 0x07 >;
		dram_zq = < 0x3939b9 >;
		dram_odt_en = < 0x31 >;
		dram_para1 = < 0x10e210e2 >;
		dram_para2 = < 0x1001 >;
		dram_mr0 = < 0x1840 >;
		dram_mr1 = < 0x40 >;
		dram_mr2 = < 0x18 >;
		dram_mr3 = < 0x02 >;
		dram_tpr0 = < 0x48a258 >;
		dram_tpr1 = < 0x1b1b28f >;
		dram_tpr2 = < 0x47028 >;
		dram_tpr3 = < 0x50005dc >;
		dram_tpr4 = < 0x00 >;
		dram_tpr5 = < 0x00 >;
		dram_tpr6 = < 0x00 >;
		dram_tpr7 = < 0x2a066198 >;
		dram_tpr8 = < 0x00 >;
		dram_tpr9 = < 0x00 >;
		dram_tpr10 = < 0x442b >;
		dram_tpr11 = < 0x13860053 >;
		dram_tpr12 = < 0x88770000 >;
		dram_tpr13 = < 0x4000100 >;
		device_type = "dram";
	};

	memory@40000000 {
		device_type = "memory";
		reg = < 0x00 0x40000000 0x00 0x40000000 >;
	};

	interrupt-controller@1c81000 {
		compatible = "arm,cortex-a15-gic\0arm,cortex-a9-gic";
		#interrupt-cells = < 0x03 >;
		#address-cells = < 0x00 >;
		device_type = "gic";
		interrupt-controller;
		reg = < 0x00 0x1c81000 0x00 0x1000 0x00 0x1c82000 0x00 0x2000 0x00 0x1c84000 0x00 0x2000 0x00 0x1c86000 0x00 0x2000 >;
		interrupts = < 0x01 0x09 0xf04 >;
		linux,phandle = < 0x01 >;
		phandle = < 0x01 >;
	};

	sunxi-chipid@1c14200 {
		compatible = "allwinner,sunxi-chipid";
		device_type = "chipid";
		reg = < 0x00 0x1c14200 0x00 0x200 >;
	};

	timer {
		compatible = "arm,armv8-timer";
		interrupts = < 0x01 0x0d 0xff01 0x01 0x0e 0xff01 0x01 0x0b 0xff01 0x01 0x0a 0xff01 >;
		clock-frequency = < 0x16e3600 >;
	};

	pmu {
		compatible = "arm,armv8-pmuv3";
		interrupts = < 0x00 0x78 0x04 0x00 0x79 0x04 0x00 0x7a 0x04 0x00 0x7b 0x04 >;
	};

	dvfs_table {
		compatible = "allwinner,dvfs_table";
		max_freq = < 0x44aa2000 >;
		min_freq = < 0x1c9c3800 >;
		lv_count = < 0x08 >;
		lv1_freq = < 0x44aa2000 >;
		lv1_volt = < 0x514 >;
		lv2_freq = < 0x41cdb400 >;
		lv2_volt = < 0x4ec >;
		lv3_freq = < 0x3c14dc00 >;
		lv3_volt = < 0x4b0 >;
		lv4_freq = < 0x30a32c00 >;
		lv4_volt = < 0x44c >;
		lv5_freq = < 0x269fb200 >;
		lv5_volt = < 0x410 >;
		lv6_freq = < 0x00 >;
		lv6_volt = < 0x410 >;
		lv7_freq = < 0x00 >;
		lv7_volt = < 0x410 >;
		lv8_freq = < 0x00 >;
		lv8_volt = < 0x410 >;
		device_type = "dvfs_table";
	};

	dramfreq {
		compatible = "allwinner,sunxi-dramfreq";
		reg = < 0x00 0x1c62000 0x00 0x1000 0x00 0x1c63000 0x00 0x1000 0x00 0x1c20000 0x00 0x800 >;
		clocks = < 0x93 0x94 0x95 >;
		status = "okay";
	};

	uboot {
	};

	gpu@0x01c40000 {
		compatible = "arm,mali-400\0arm,mali-utgard";
		reg = < 0x00 0x1c40000 0x00 0x10000 >;
		interrupts = < 0x00 0x61 0x04 0x00 0x62 0x04 0x00 0x63 0x04 0x00 0x64 0x04 0x00 0x66 0x04 0x00 0x67 0x04 >;
		interrupt-names = "IRQGP\0IRQGPMMU\0IRQPP0\0IRQPPMMU0\0IRQPP1\0IRQPPMMU1";
		clocks = < 0x96 0x97 >;
		device_type = "gpu_mali400_0";
		normal_freq = < 0x1c8 >;
		scene_ctrl_status = < 0x00 >;
		temp_ctrl_status = < 0x01 >;
	};

	wlan {
		compatible = "allwinner,sunxi-wlan";
		wlan_io_regulator = "vcc-wifi-io";
		wlan_busnum = < 0x01 >;
		status = "okay";
		device_type = "wlan";
		clocks;
		wlan_power;
		wlan_regon = < 0x79 0x0b 0x02 0x01 0xffffffff 0xffffffff 0x00 >;
		wlan_hostwake = < 0x79 0x0b 0x03 0x06 0xffffffff 0xffffffff 0x00 >;
		efuse_map_name = "wifi_efuse_8723cs_A114.map";
	};

	bt {
		compatible = "allwinner,sunxi-bt";
		bt_io_regulator = "vcc-wifi-io";
		status = "okay";
		device_type = "bt";
		clocks;
		bt_power;
		bt_rst_n = < 0x79 0x0b 0x04 0x01 0xffffffff 0xffffffff 0x00 >;
	};

	btlpm {
		compatible = "allwinner,sunxi-btlpm";
		uart_index = < 0x01 >;
		status = "okay";
		device_type = "btlpm";
		bt_wake = < 0x79 0x0b 0x06 0x01 0xffffffff 0xffffffff 0x01 >;
		bt_hostwake = < 0x79 0x0b 0x05 0x06 0xffffffff 0xffffffff 0x00 >;
	};

	hall {
		compatible = "allwinner,hall";
		hall_pos = < 0x00 >;
		status = "okay";
		device_type = "hall";
		hall_power = "hall-vcc-18";
		hall_power_vol = < 0x708 >;
		hall_gpio = < 0x79 0x0b 0x0c 0x06 0xffffffff 0xffffffff 0x00 >;
	};
};
